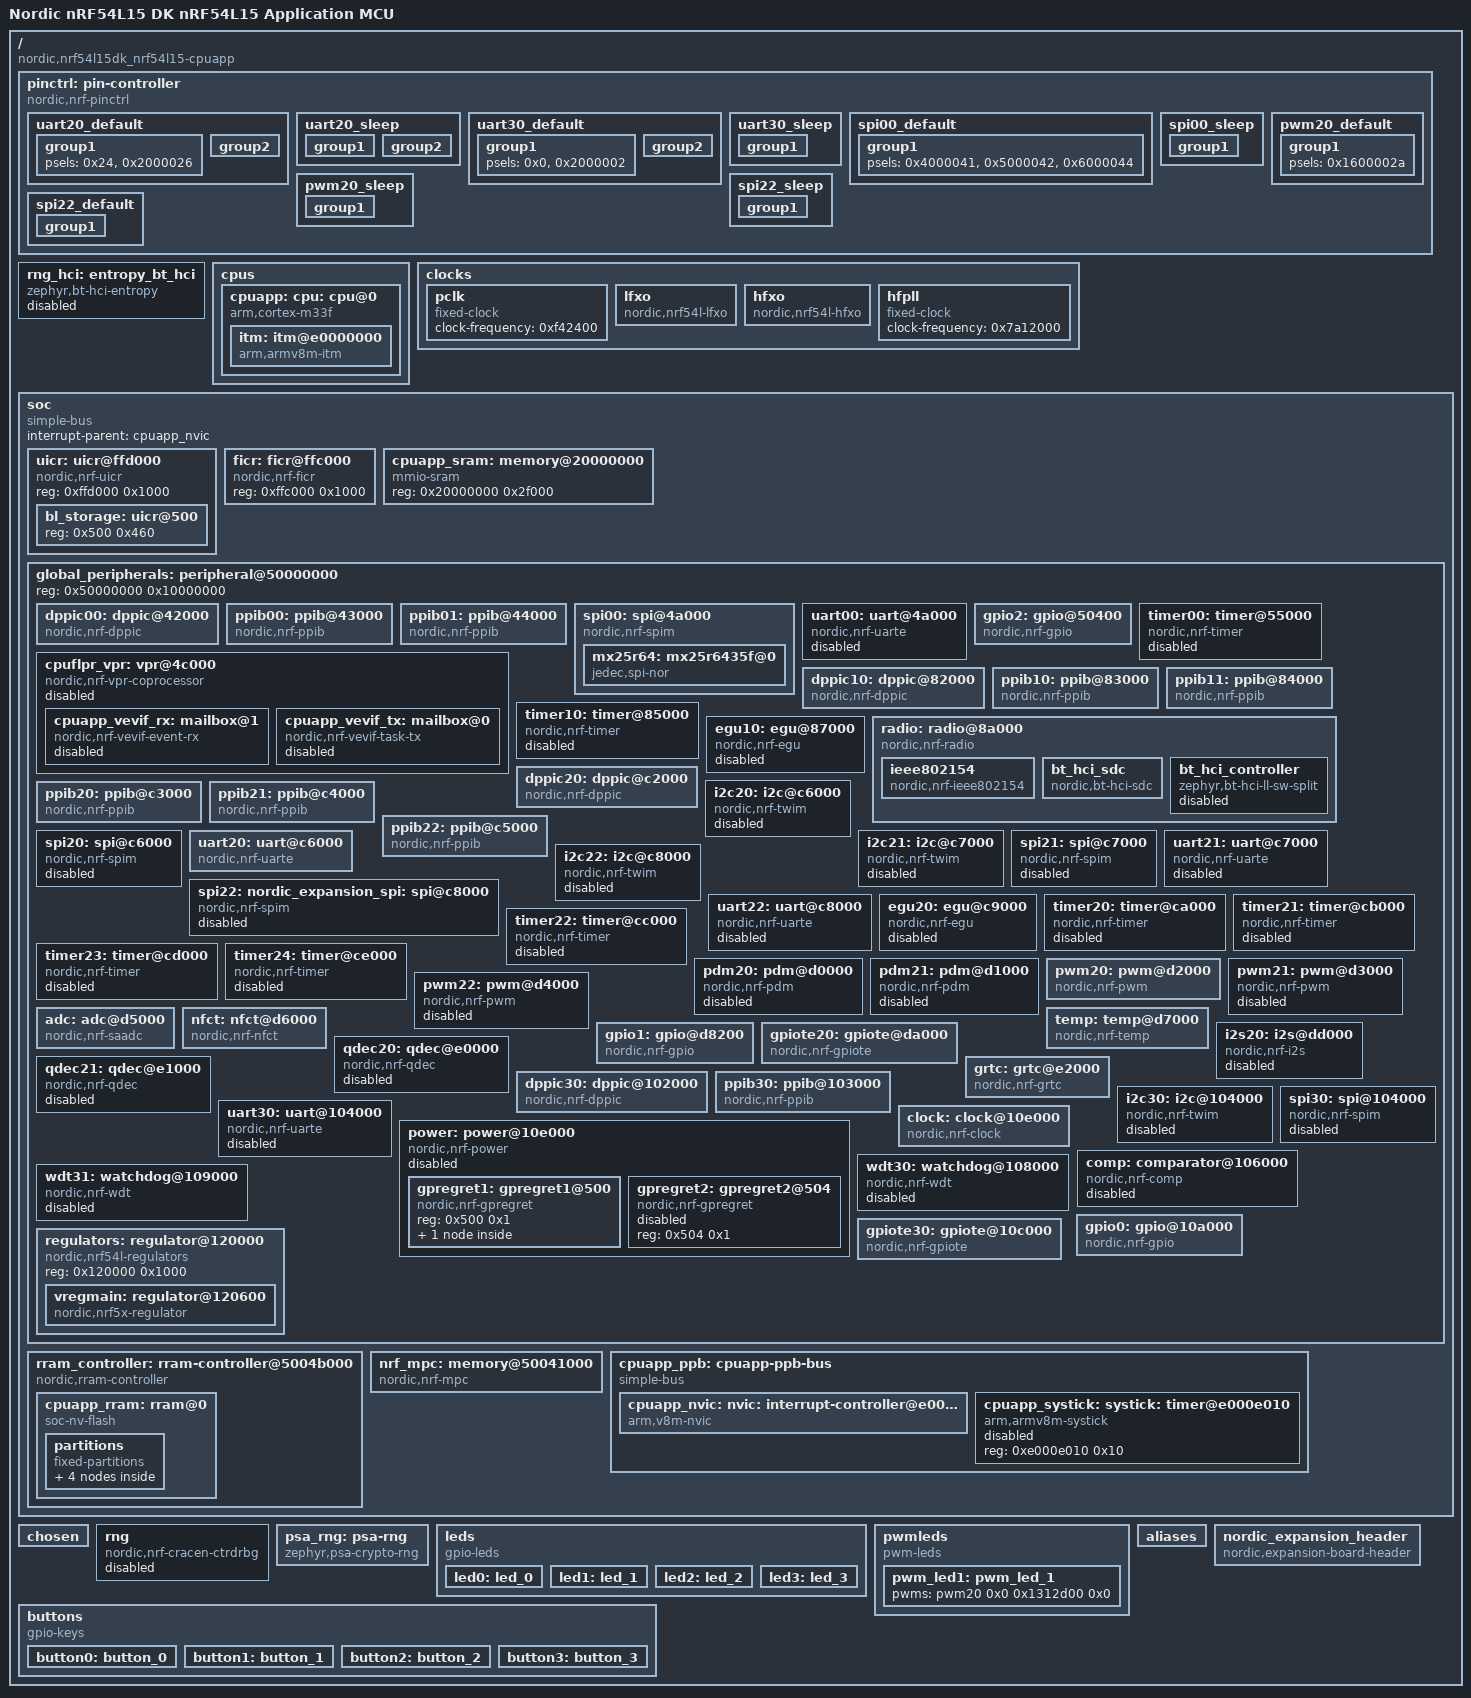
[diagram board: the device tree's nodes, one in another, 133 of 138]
/dts-v1/;

/* node '/' defined in zephyr/dts/vendor/nordic/nrf_common.dtsi:25 */
/ {
	#address-cells = < 0x1 >;                              /* in zephyr/dts/vendor/nordic/nrf54l_05_10_15.dtsi:19 */
	#size-cells = < 0x1 >;                                 /* in zephyr/dts/vendor/nordic/nrf54l_05_10_15.dtsi:20 */
	compatible = "nordic,nrf54l15dk_nrf54l15-cpuapp";      /* in zephyr/boards/nordic/nrf54l15dk/nrf54l15dk_nrf54l15_cpuapp.dts:13 */
	model = "Nordic nRF54L15 DK nRF54L15 Application MCU"; /* in zephyr/boards/nordic/nrf54l15dk/nrf54l15dk_nrf54l15_cpuapp.dts:14 */

	/* node '/pin-controller' defined in zephyr/dts/vendor/nordic/nrf_common.dtsi:26 */
	pinctrl: pin-controller {
		compatible = "nordic,nrf-pinctrl"; /* in zephyr/dts/vendor/nordic/nrf_common.dtsi:31 */

		/* node '/pin-controller/uart20_default' defined in zephyr/boards/nordic/nrf54l15dk/nrf54l15dk_nrf54l_05_10_15-pinctrl.dtsi:7 */
		uart20_default: uart20_default {
			phandle = < 0x7 >; /* in zephyr/boards/nordic/nrf54l15dk/nrf54l15dk_common.dtsi:114 */

			/* node '/pin-controller/uart20_default/group1' defined in zephyr/boards/nordic/nrf54l15dk/nrf54l15dk_nrf54l_05_10_15-pinctrl.dtsi:8 */
			group1 {
				psels = < 0x24 >,
				        < 0x2000026 >; /* in zephyr/boards/nordic/nrf54l15dk/nrf54l15dk_nrf54l_05_10_15-pinctrl.dtsi:9 */
			};

			/* node '/pin-controller/uart20_default/group2' defined in zephyr/boards/nordic/nrf54l15dk/nrf54l15dk_nrf54l_05_10_15-pinctrl.dtsi:13 */
			group2 {
				psels = < 0x1000025 >,
				        < 0x3000027 >; /* in zephyr/boards/nordic/nrf54l15dk/nrf54l15dk_nrf54l_05_10_15-pinctrl.dtsi:14 */
				bias-pull-up;          /* in zephyr/boards/nordic/nrf54l15dk/nrf54l15dk_nrf54l_05_10_15-pinctrl.dtsi:16 */
			};
		};

		/* node '/pin-controller/uart20_sleep' defined in zephyr/boards/nordic/nrf54l15dk/nrf54l15dk_nrf54l_05_10_15-pinctrl.dtsi:20 */
		uart20_sleep: uart20_sleep {
			phandle = < 0x8 >; /* in zephyr/boards/nordic/nrf54l15dk/nrf54l15dk_common.dtsi:115 */

			/* node '/pin-controller/uart20_sleep/group1' defined in zephyr/boards/nordic/nrf54l15dk/nrf54l15dk_nrf54l_05_10_15-pinctrl.dtsi:21 */
			group1 {
				psels = < 0x1000025 >,
				        < 0x2000026 >,
				        < 0x3000027 >; /* in zephyr/boards/nordic/nrf54l15dk/nrf54l15dk_nrf54l_05_10_15-pinctrl.dtsi:22 */
				low-power-enable;      /* in zephyr/boards/nordic/nrf54l15dk/nrf54l15dk_nrf54l_05_10_15-pinctrl.dtsi:25 */
			};

			/* node '/pin-controller/uart20_sleep/group2' defined in zephyr/boards/nordic/nrf54l15dk/nrf54l15dk_nrf54l_05_10_15-pinctrl.dtsi:28 */
			group2 {
				psels = < 0x24 >; /* in zephyr/boards/nordic/nrf54l15dk/nrf54l15dk_nrf54l_05_10_15-pinctrl.dtsi:29 */
				low-power-enable; /* in zephyr/boards/nordic/nrf54l15dk/nrf54l15dk_nrf54l_05_10_15-pinctrl.dtsi:30 */
				bias-pull-up;     /* in zephyr/boards/nordic/nrf54l15dk/nrf54l15dk_nrf54l_05_10_15-pinctrl.dtsi:31 */
			};
		};

		/* node '/pin-controller/uart30_default' defined in zephyr/boards/nordic/nrf54l15dk/nrf54l15dk_nrf54l_05_10_15-pinctrl.dtsi:35 */
		uart30_default: uart30_default {
			phandle = < 0x11 >; /* in zephyr/boards/nordic/nrf54l15dk/nrf54l15dk_common.dtsi:121 */

			/* node '/pin-controller/uart30_default/group1' defined in zephyr/boards/nordic/nrf54l15dk/nrf54l15dk_nrf54l_05_10_15-pinctrl.dtsi:36 */
			group1 {
				psels = < 0x0 >,
				        < 0x2000002 >; /* in zephyr/boards/nordic/nrf54l15dk/nrf54l15dk_nrf54l_05_10_15-pinctrl.dtsi:37 */
			};

			/* node '/pin-controller/uart30_default/group2' defined in zephyr/boards/nordic/nrf54l15dk/nrf54l15dk_nrf54l_05_10_15-pinctrl.dtsi:41 */
			group2 {
				psels = < 0x1000001 >,
				        < 0x3000003 >; /* in zephyr/boards/nordic/nrf54l15dk/nrf54l15dk_nrf54l_05_10_15-pinctrl.dtsi:42 */
				bias-pull-up;          /* in zephyr/boards/nordic/nrf54l15dk/nrf54l15dk_nrf54l_05_10_15-pinctrl.dtsi:44 */
			};
		};

		/* node '/pin-controller/uart30_sleep' defined in zephyr/boards/nordic/nrf54l15dk/nrf54l15dk_nrf54l_05_10_15-pinctrl.dtsi:48 */
		uart30_sleep: uart30_sleep {
			phandle = < 0x12 >; /* in zephyr/boards/nordic/nrf54l15dk/nrf54l15dk_common.dtsi:122 */

			/* node '/pin-controller/uart30_sleep/group1' defined in zephyr/boards/nordic/nrf54l15dk/nrf54l15dk_nrf54l_05_10_15-pinctrl.dtsi:49 */
			group1 {
				psels = < 0x0 >,
				        < 0x1000001 >,
				        < 0x2000002 >,
				        < 0x3000003 >; /* in zephyr/boards/nordic/nrf54l15dk/nrf54l15dk_nrf54l_05_10_15-pinctrl.dtsi:50 */
				low-power-enable;      /* in zephyr/boards/nordic/nrf54l15dk/nrf54l15dk_nrf54l_05_10_15-pinctrl.dtsi:54 */
			};
		};

		/* node '/pin-controller/spi00_default' defined in zephyr/boards/nordic/nrf54l15dk/nrf54l15dk_nrf54l_05_10_15-pinctrl.dtsi:58 */
		spi00_default: spi00_default {
			phandle = < 0x4 >; /* in zephyr/boards/nordic/nrf54l15dk/nrf54l_05_10_15_cpuapp_common.dtsi:117 */

			/* node '/pin-controller/spi00_default/group1' defined in zephyr/boards/nordic/nrf54l15dk/nrf54l15dk_nrf54l_05_10_15-pinctrl.dtsi:59 */
			group1 {
				psels = < 0x4000041 >,
				        < 0x5000042 >,
				        < 0x6000044 >; /* in zephyr/boards/nordic/nrf54l15dk/nrf54l15dk_nrf54l_05_10_15-pinctrl.dtsi:60 */
			};
		};

		/* node '/pin-controller/spi00_sleep' defined in zephyr/boards/nordic/nrf54l15dk/nrf54l15dk_nrf54l_05_10_15-pinctrl.dtsi:66 */
		spi00_sleep: spi00_sleep {
			phandle = < 0x5 >; /* in zephyr/boards/nordic/nrf54l15dk/nrf54l_05_10_15_cpuapp_common.dtsi:118 */

			/* node '/pin-controller/spi00_sleep/group1' defined in zephyr/boards/nordic/nrf54l15dk/nrf54l15dk_nrf54l_05_10_15-pinctrl.dtsi:67 */
			group1 {
				psels = < 0x4000041 >,
				        < 0x5000042 >,
				        < 0x6000044 >; /* in zephyr/boards/nordic/nrf54l15dk/nrf54l15dk_nrf54l_05_10_15-pinctrl.dtsi:68 */
				low-power-enable;      /* in zephyr/boards/nordic/nrf54l15dk/nrf54l15dk_nrf54l_05_10_15-pinctrl.dtsi:71 */
			};
		};

		/* node '/pin-controller/pwm20_default' defined in zephyr/boards/nordic/nrf54l15dk/nrf54l15dk_nrf54l_05_10_15-pinctrl.dtsi:75 */
		pwm20_default: pwm20_default {
			phandle = < 0xc >; /* in zephyr/boards/nordic/nrf54l15dk/nrf54l15dk_common.dtsi:128 */

			/* node '/pin-controller/pwm20_default/group1' defined in zephyr/boards/nordic/nrf54l15dk/nrf54l15dk_nrf54l_05_10_15-pinctrl.dtsi:76 */
			group1 {
				psels = < 0x1600002a >; /* in zephyr/boards/nordic/nrf54l15dk/nrf54l15dk_nrf54l_05_10_15-pinctrl.dtsi:77 */
			};
		};

		/* node '/pin-controller/pwm20_sleep' defined in zephyr/boards/nordic/nrf54l15dk/nrf54l15dk_nrf54l_05_10_15-pinctrl.dtsi:81 */
		pwm20_sleep: pwm20_sleep {
			phandle = < 0xd >; /* in zephyr/boards/nordic/nrf54l15dk/nrf54l15dk_common.dtsi:129 */

			/* node '/pin-controller/pwm20_sleep/group1' defined in zephyr/boards/nordic/nrf54l15dk/nrf54l15dk_nrf54l_05_10_15-pinctrl.dtsi:82 */
			group1 {
				psels = < 0x1600002a >; /* in zephyr/boards/nordic/nrf54l15dk/nrf54l15dk_nrf54l_05_10_15-pinctrl.dtsi:83 */
				low-power-enable;       /* in zephyr/boards/nordic/nrf54l15dk/nrf54l15dk_nrf54l_05_10_15-pinctrl.dtsi:84 */
			};
		};

		/* node '/pin-controller/spi22_default' defined in zephyr/boards/nordic/nrf54l15dk/nrf54l15dk_nrf54l_05_10_15-pinctrl.dtsi:103 */
		spi22_default: spi22_default {
			phandle = < 0xa >; /* in zephyr/boards/nordic/nrf54l15dk/nrf54l_05_10_15_cpuapp_common.dtsi:149 */

			/* node '/pin-controller/spi22_default/group1' defined in zephyr/boards/nordic/nrf54l15dk/nrf54l15dk_nrf54l_05_10_15-pinctrl.dtsi:104 */
			group1 {
				psels = < 0x400002b >,
				        < 0x6000027 >,
				        < 0x5000026 >; /* in zephyr/boards/nordic/nrf54l15dk/nrf54l15dk_nrf54l_05_10_15-pinctrl.dtsi:105 */
				bias-pull-down;        /* in zephyr/boards/nordic/nrf54l15dk/nrf54l15dk_nrf54l_05_10_15-pinctrl.dtsi:108 */
			};
		};

		/* node '/pin-controller/spi22_sleep' defined in zephyr/boards/nordic/nrf54l15dk/nrf54l15dk_nrf54l_05_10_15-pinctrl.dtsi:112 */
		spi22_sleep: spi22_sleep {
			phandle = < 0xb >; /* in zephyr/boards/nordic/nrf54l15dk/nrf54l_05_10_15_cpuapp_common.dtsi:150 */

			/* node '/pin-controller/spi22_sleep/group1' defined in zephyr/boards/nordic/nrf54l15dk/nrf54l15dk_nrf54l_05_10_15-pinctrl.dtsi:113 */
			group1 {
				psels = < 0x400002b >,
				        < 0x6000027 >,
				        < 0x5000026 >; /* in zephyr/boards/nordic/nrf54l15dk/nrf54l15dk_nrf54l_05_10_15-pinctrl.dtsi:114 */
				bias-pull-down;        /* in zephyr/boards/nordic/nrf54l15dk/nrf54l15dk_nrf54l_05_10_15-pinctrl.dtsi:117 */
				low-power-enable;      /* in zephyr/boards/nordic/nrf54l15dk/nrf54l15dk_nrf54l_05_10_15-pinctrl.dtsi:118 */
			};
		};
	};

	/* node '/entropy_bt_hci' defined in zephyr/dts/vendor/nordic/nrf_common.dtsi:34 */
	rng_hci: entropy_bt_hci {
		compatible = "zephyr,bt-hci-entropy"; /* in zephyr/dts/vendor/nordic/nrf_common.dtsi:35 */
		status = "disabled";                  /* in zephyr/dts/vendor/nordic/nrf_common.dtsi:36 */
	};

	/* node '/cpus' defined in zephyr/dts/vendor/nordic/nrf54l_05_10_15.dtsi:22 */
	cpus {
		#address-cells = < 0x1 >; /* in zephyr/dts/vendor/nordic/nrf54l_05_10_15.dtsi:23 */
		#size-cells = < 0x0 >;    /* in zephyr/dts/vendor/nordic/nrf54l_05_10_15.dtsi:24 */

		/* node '/cpus/cpu@0' defined in zephyr/dts/vendor/nordic/nrf54l_05_10_15.dtsi:26 */
		cpuapp: cpu: cpu@0 {
			compatible = "arm,cortex-m33f"; /* in zephyr/dts/vendor/nordic/nrf54l_05_10_15.dtsi:27 */
			reg = < 0x0 >;                  /* in zephyr/dts/vendor/nordic/nrf54l_05_10_15.dtsi:28 */
			device_type = "cpu";            /* in zephyr/dts/vendor/nordic/nrf54l_05_10_15.dtsi:29 */
			clocks = < &hfpll >;            /* in zephyr/dts/vendor/nordic/nrf54l_05_10_15.dtsi:30 */
			#address-cells = < 0x1 >;       /* in zephyr/dts/vendor/nordic/nrf54l_05_10_15.dtsi:31 */
			#size-cells = < 0x1 >;          /* in zephyr/dts/vendor/nordic/nrf54l_05_10_15.dtsi:32 */

			/* node '/cpus/cpu@0/itm@e0000000' defined in zephyr/dts/vendor/nordic/nrf54l_05_10_15.dtsi:34 */
			itm: itm@e0000000 {
				compatible = "arm,armv8m-itm";     /* in zephyr/dts/vendor/nordic/nrf54l_05_10_15.dtsi:35 */
				reg = < 0xe0000000 0x1000 >;       /* in zephyr/dts/vendor/nordic/nrf54l_05_10_15.dtsi:36 */
				swo-ref-frequency = < 0x7a12000 >; /* in zephyr/dts/vendor/nordic/nrf54l_05_10_15.dtsi:37 */
			};
		};
	};

	/* node '/clocks' defined in zephyr/dts/vendor/nordic/nrf54l_05_10_15.dtsi:52 */
	clocks {

		/* node '/clocks/pclk' defined in zephyr/dts/vendor/nordic/nrf54l_05_10_15.dtsi:53 */
		pclk: pclk {
			compatible = "fixed-clock";     /* in zephyr/dts/vendor/nordic/nrf54l_05_10_15.dtsi:54 */
			#clock-cells = < 0x0 >;         /* in zephyr/dts/vendor/nordic/nrf54l_05_10_15.dtsi:55 */
			clock-frequency = < 0xf42400 >; /* in zephyr/dts/vendor/nordic/nrf54l_05_10_15.dtsi:56 */
			phandle = < 0x10 >;             /* in zephyr/dts/vendor/nordic/nrf54l_05_10_15.dtsi:595 */
		};

		/* node '/clocks/lfxo' defined in zephyr/dts/vendor/nordic/nrf54l_05_10_15.dtsi:59 */
		lfxo: lfxo {
			compatible = "nordic,nrf54l-lfxo";        /* in zephyr/dts/vendor/nordic/nrf54l_05_10_15.dtsi:60 */
			#clock-cells = < 0x0 >;                   /* in zephyr/dts/vendor/nordic/nrf54l_05_10_15.dtsi:61 */
			clock-frequency = < 0x8000 >;             /* in zephyr/dts/vendor/nordic/nrf54l_05_10_15.dtsi:62 */
			load-capacitors = "internal";             /* in zephyr/boards/nordic/nrf54l15dk/nrf54l_05_10_15_cpuapp_common.dtsi:35 */
			load-capacitance-femtofarad = < 0x4268 >; /* in zephyr/boards/nordic/nrf54l15dk/nrf54l_05_10_15_cpuapp_common.dtsi:36 */
			phandle = < 0xf >;                        /* in zephyr/dts/vendor/nordic/nrf54l_05_10_15.dtsi:595 */
		};

		/* node '/clocks/hfxo' defined in zephyr/dts/vendor/nordic/nrf54l_05_10_15.dtsi:65 */
		hfxo: hfxo {
			compatible = "nordic,nrf54l-hfxo";        /* in zephyr/dts/vendor/nordic/nrf54l_05_10_15.dtsi:66 */
			#clock-cells = < 0x0 >;                   /* in zephyr/dts/vendor/nordic/nrf54l_05_10_15.dtsi:67 */
			clock-frequency = < 0x1e84800 >;          /* in zephyr/dts/vendor/nordic/nrf54l_05_10_15.dtsi:68 */
			startup-time-us = < 0x672 >;              /* in zephyr/dts/vendor/nordic/nrf54l_05_10_15.dtsi:69 */
			load-capacitors = "internal";             /* in zephyr/boards/nordic/nrf54l15dk/nrf54l_05_10_15_cpuapp_common.dtsi:40 */
			load-capacitance-femtofarad = < 0x3a98 >; /* in zephyr/boards/nordic/nrf54l15dk/nrf54l_05_10_15_cpuapp_common.dtsi:41 */
			phandle = < 0x6 >;                        /* in zephyr/dts/vendor/nordic/nrf54l_05_10_15.dtsi:242 */
		};

		/* node '/clocks/hfpll' defined in zephyr/dts/vendor/nordic/nrf54l_05_10_15.dtsi:72 */
		hfpll: hfpll {
			compatible = "fixed-clock";      /* in zephyr/dts/vendor/nordic/nrf54l_05_10_15.dtsi:73 */
			#clock-cells = < 0x0 >;          /* in zephyr/dts/vendor/nordic/nrf54l_05_10_15.dtsi:74 */
			clock-frequency = < 0x7a12000 >; /* in zephyr/dts/vendor/nordic/nrf54l_05_10_15.dtsi:75 */
			phandle = < 0x1 >;               /* in zephyr/dts/vendor/nordic/nrf54l_05_10_15.dtsi:30 */
		};
	};

	/* node '/soc' defined in zephyr/dts/vendor/nordic/nrf54l_05_10_15.dtsi:79 */
	soc {
		#address-cells = < 0x1 >;            /* in zephyr/dts/vendor/nordic/nrf54l_05_10_15.dtsi:80 */
		#size-cells = < 0x1 >;               /* in zephyr/dts/vendor/nordic/nrf54l_05_10_15.dtsi:81 */
		compatible = "simple-bus";           /* in zephyr/dts/arm/nordic/nrf54l_05_10_15_cpuapp.dtsi:28 */
		interrupt-parent = < &cpuapp_nvic >; /* in zephyr/dts/arm/nordic/nrf54l_05_10_15_cpuapp.dtsi:29 */
		ranges;                              /* in zephyr/dts/arm/nordic/nrf54l_05_10_15_cpuapp.dtsi:30 */

		/* node '/soc/uicr@ffd000' defined in zephyr/dts/vendor/nordic/nrf54l_05_10_15.dtsi:86 */
		uicr: uicr@ffd000 {
			compatible = "nordic,nrf-uicr";   /* in zephyr/dts/vendor/nordic/nrf54l_05_10_15.dtsi:87 */
			reg = < 0xffd000 0x1000 >;        /* in zephyr/dts/vendor/nordic/nrf54l_05_10_15.dtsi:88 */
			ranges = < 0x0 0xffd000 0x1000 >; /* in zephyr/dts/vendor/nordic/nrf54l_05_10_15.dtsi:89 */
			#address-cells = < 0x1 >;         /* in zephyr/dts/vendor/nordic/nrf54l_05_10_15.dtsi:90 */
			#size-cells = < 0x1 >;            /* in zephyr/dts/vendor/nordic/nrf54l_05_10_15.dtsi:91 */

			/* node '/soc/uicr@ffd000/uicr@500' defined in zephyr/dts/vendor/nordic/nrf54l15_cpuapp_partition.dtsi:36 */
			bl_storage: uicr@500 {
				reg = < 0x500 0x460 >; /* in zephyr/dts/vendor/nordic/nrf54l15_cpuapp_partition.dtsi:37 */
			};
		};

		/* node '/soc/ficr@ffc000' defined in zephyr/dts/vendor/nordic/nrf54l_05_10_15.dtsi:95 */
		ficr: ficr@ffc000 {
			compatible = "nordic,nrf-ficr"; /* in zephyr/dts/vendor/nordic/nrf54l_05_10_15.dtsi:96 */
			reg = < 0xffc000 0x1000 >;      /* in zephyr/dts/vendor/nordic/nrf54l_05_10_15.dtsi:97 */
			#nordic,ficr-cells = < 0x1 >;   /* in zephyr/dts/vendor/nordic/nrf54l_05_10_15.dtsi:98 */
		};

		/* node '/soc/memory@20000000' defined in zephyr/dts/vendor/nordic/nrf54l_05_10_15.dtsi:101 */
		cpuapp_sram: memory@20000000 {
			compatible = "mmio-sram";            /* in zephyr/dts/vendor/nordic/nrf54l_05_10_15.dtsi:102 */
			#address-cells = < 0x1 >;            /* in zephyr/dts/vendor/nordic/nrf54l_05_10_15.dtsi:103 */
			#size-cells = < 0x1 >;               /* in zephyr/dts/vendor/nordic/nrf54l_05_10_15.dtsi:104 */
			reg = < 0x20000000 0x2f000 >;        /* in zephyr/dts/vendor/nordic/nrf54l15.dtsi:10 */
			ranges = < 0x0 0x20000000 0x2f000 >; /* in zephyr/dts/vendor/nordic/nrf54l15.dtsi:11 */
			status = "okay";                     /* in zephyr/boards/nordic/nrf54l15dk/nrf54l_05_10_15_cpuapp_common.dtsi:31 */
		};

		/* node '/soc/peripheral@50000000' defined in zephyr/dts/vendor/nordic/nrf54l_05_10_15.dtsi:114 */
		global_peripherals: peripheral@50000000 {
			reg = < 0x50000000 0x10000000 >;        /* in zephyr/dts/vendor/nordic/nrf54l_05_10_15.dtsi:115 */
			#address-cells = < 0x1 >;               /* in zephyr/dts/vendor/nordic/nrf54l_05_10_15.dtsi:116 */
			#size-cells = < 0x1 >;                  /* in zephyr/dts/vendor/nordic/nrf54l_05_10_15.dtsi:117 */
			ranges = < 0x0 0x50000000 0x10000000 >; /* in zephyr/dts/vendor/nordic/nrf54l_05_10_15.dtsi:118 */

			/* node '/soc/peripheral@50000000/dppic@42000' defined in zephyr/dts/vendor/nordic/nrf54l_05_10_15.dtsi:121 */
			dppic00: dppic@42000 {
				compatible = "nordic,nrf-dppic"; /* in zephyr/dts/vendor/nordic/nrf54l_05_10_15.dtsi:122 */
				reg = < 0x42000 0x808 >;         /* in zephyr/dts/vendor/nordic/nrf54l_05_10_15.dtsi:123 */
				channels = < 0x8 >;              /* in zephyr/dts/vendor/nordic/nrf54l_05_10_15.dtsi:125 */
				groups = < 0x2 >;                /* in zephyr/dts/vendor/nordic/nrf54l_05_10_15.dtsi:126 */
				status = "okay";                 /* in zephyr/dts/arm/nordic/nrf54l_05_10_15_cpuapp.dtsi:100 */
			};

			/* node '/soc/peripheral@50000000/ppib@43000' defined in zephyr/dts/vendor/nordic/nrf54l_05_10_15.dtsi:129 */
			ppib00: ppib@43000 {
				compatible = "nordic,nrf-ppib"; /* in zephyr/dts/vendor/nordic/nrf54l_05_10_15.dtsi:130 */
				reg = < 0x43000 0x1000 >;       /* in zephyr/dts/vendor/nordic/nrf54l_05_10_15.dtsi:131 */
				channels = < 0x8 >;             /* in zephyr/dts/vendor/nordic/nrf54l_05_10_15.dtsi:133 */
				status = "okay";                /* in zephyr/dts/arm/nordic/nrf54l_05_10_15_cpuapp.dtsi:116 */
			};

			/* node '/soc/peripheral@50000000/ppib@44000' defined in zephyr/dts/vendor/nordic/nrf54l_05_10_15.dtsi:136 */
			ppib01: ppib@44000 {
				compatible = "nordic,nrf-ppib"; /* in zephyr/dts/vendor/nordic/nrf54l_05_10_15.dtsi:137 */
				reg = < 0x44000 0x1000 >;       /* in zephyr/dts/vendor/nordic/nrf54l_05_10_15.dtsi:138 */
				channels = < 0x8 >;             /* in zephyr/dts/vendor/nordic/nrf54l_05_10_15.dtsi:140 */
				status = "okay";                /* in zephyr/dts/arm/nordic/nrf54l_05_10_15_cpuapp.dtsi:120 */
			};

			/* node '/soc/peripheral@50000000/spi@4a000' defined in zephyr/dts/vendor/nordic/nrf54l_05_10_15.dtsi:143 */
			spi00: spi@4a000 {
				compatible = "nordic,nrf-spim"; /* in zephyr/dts/vendor/nordic/nrf54l_05_10_15.dtsi:150 */
				#address-cells = < 0x1 >;       /* in zephyr/dts/vendor/nordic/nrf54l_05_10_15.dtsi:151 */
				#size-cells = < 0x0 >;          /* in zephyr/dts/vendor/nordic/nrf54l_05_10_15.dtsi:152 */
				reg = < 0x4a000 0x1000 >;       /* in zephyr/dts/vendor/nordic/nrf54l_05_10_15.dtsi:153 */
				interrupts = < 0x4a 0x1 >;      /* in zephyr/dts/vendor/nordic/nrf54l_05_10_15.dtsi:154 */
				clocks = < &hfpll >;            /* in zephyr/dts/vendor/nordic/nrf54l_05_10_15.dtsi:155 */
				max-frequency = < 0x1e84800 >;  /* in zephyr/dts/vendor/nordic/nrf54l_05_10_15.dtsi:156 */
				easydma-maxcnt-bits = < 0x10 >; /* in zephyr/dts/vendor/nordic/nrf54l_05_10_15.dtsi:157 */
				rx-delay-supported;             /* in zephyr/dts/vendor/nordic/nrf54l_05_10_15.dtsi:158 */
				rx-delay = < 0x1 >;             /* in zephyr/dts/vendor/nordic/nrf54l_05_10_15.dtsi:159 */
				status = "okay";                /* in zephyr/boards/nordic/nrf54l15dk/nrf54l_05_10_15_cpuapp_common.dtsi:115 */
				cs-gpios = < &gpio2 0x5 0x1 >;  /* in zephyr/boards/nordic/nrf54l15dk/nrf54l_05_10_15_cpuapp_common.dtsi:116 */
				pinctrl-0 = < &spi00_default >; /* in zephyr/boards/nordic/nrf54l15dk/nrf54l_05_10_15_cpuapp_common.dtsi:117 */
				pinctrl-1 = < &spi00_sleep >;   /* in zephyr/boards/nordic/nrf54l15dk/nrf54l_05_10_15_cpuapp_common.dtsi:118 */
				pinctrl-names = "default",
				                "sleep";        /* in zephyr/boards/nordic/nrf54l15dk/nrf54l_05_10_15_cpuapp_common.dtsi:119 */

				/* node '/soc/peripheral@50000000/spi@4a000/mx25r6435f@0' defined in zephyr/boards/nordic/nrf54l15dk/nrf54l_05_10_15_cpuapp_common.dtsi:121 */
				mx25r64: mx25r6435f@0 {
					compatible = "jedec,spi-nor";                                                                 /* in zephyr/boards/nordic/nrf54l15dk/nrf54l_05_10_15_cpuapp_common.dtsi:122 */
					status = "okay";                                                                              /* in zephyr/boards/nordic/nrf54l15dk/nrf54l_05_10_15_cpuapp_common.dtsi:123 */
					reg = < 0x0 >;                                                                                /* in zephyr/boards/nordic/nrf54l15dk/nrf54l_05_10_15_cpuapp_common.dtsi:124 */
					spi-max-frequency = < 0x7a1200 >;                                                             /* in zephyr/boards/nordic/nrf54l15dk/nrf54l_05_10_15_cpuapp_common.dtsi:125 */
					jedec-id = [ C2 28 17 ];                                                                      /* in zephyr/boards/nordic/nrf54l15dk/nrf54l_05_10_15_cpuapp_common.dtsi:126 */
					sfdp-bfp = [ E5 20 F1 FF FF FF FF 03 44 EB 08 6B 08 3B 04 BB EE FF FF FF FF FF 00 FF FF FF 00
					             FF 0C 20 0F 52 10 D8 00 FF 23 72 F5 00 82 ED 04 CC 44 83 48 44 30 B0 30 B0 F7 C4
					             D5 5C 00 BE 29 FF F0 D0 FF FF ];                                                 /* in zephyr/boards/nordic/nrf54l15dk/nrf54l_05_10_15_cpuapp_common.dtsi:127 */
					size = < 0x4000000 >;                                                                         /* in zephyr/boards/nordic/nrf54l15dk/nrf54l_05_10_15_cpuapp_common.dtsi:131 */
					has-dpd;                                                                                      /* in zephyr/boards/nordic/nrf54l15dk/nrf54l_05_10_15_cpuapp_common.dtsi:132 */
					t-enter-dpd = < 0x2710 >;                                                                     /* in zephyr/boards/nordic/nrf54l15dk/nrf54l_05_10_15_cpuapp_common.dtsi:133 */
					t-exit-dpd = < 0x88b8 >;                                                                      /* in zephyr/boards/nordic/nrf54l15dk/nrf54l_05_10_15_cpuapp_common.dtsi:134 */
					reset-gpios = < &gpio2 0x0 0x1 >;                                                             /* in zephyr/boards/nordic/nrf54l15dk/nrf54l_05_10_15_cpuapp_common.dtsi:135 */
				};
			};

			/* node '/soc/peripheral@50000000/uart@4a000' defined in zephyr/dts/vendor/nordic/nrf54l_05_10_15.dtsi:163 */
			uart00: uart@4a000 {
				compatible = "nordic,nrf-uarte"; /* in zephyr/dts/vendor/nordic/nrf54l_05_10_15.dtsi:164 */
				reg = < 0x4a000 0x1000 >;        /* in zephyr/dts/vendor/nordic/nrf54l_05_10_15.dtsi:165 */
				interrupts = < 0x4a 0x1 >;       /* in zephyr/dts/vendor/nordic/nrf54l_05_10_15.dtsi:166 */
				clocks = < &hfpll >;             /* in zephyr/dts/vendor/nordic/nrf54l_05_10_15.dtsi:167 */
				status = "disabled";             /* in zephyr/dts/vendor/nordic/nrf54l_05_10_15.dtsi:168 */
				endtx-stoptx-supported;          /* in zephyr/dts/vendor/nordic/nrf54l_05_10_15.dtsi:169 */
				frame-timeout-supported;         /* in zephyr/dts/vendor/nordic/nrf54l_05_10_15.dtsi:170 */
			};

			/* node '/soc/peripheral@50000000/vpr@4c000' defined in zephyr/dts/vendor/nordic/nrf54l_05_10_15.dtsi:173 */
			cpuflpr_vpr: vpr@4c000 {
				compatible = "nordic,nrf-vpr-coprocessor"; /* in zephyr/dts/vendor/nordic/nrf54l_05_10_15.dtsi:174 */
				reg = < 0x4c000 0x1000 >;                  /* in zephyr/dts/vendor/nordic/nrf54l_05_10_15.dtsi:175 */
				ranges = < 0x0 0x4c000 0x1000 >;           /* in zephyr/dts/vendor/nordic/nrf54l_05_10_15.dtsi:176 */
				#address-cells = < 0x1 >;                  /* in zephyr/dts/vendor/nordic/nrf54l_05_10_15.dtsi:177 */
				#size-cells = < 0x1 >;                     /* in zephyr/dts/vendor/nordic/nrf54l_05_10_15.dtsi:178 */
				status = "disabled";                       /* in zephyr/dts/vendor/nordic/nrf54l_05_10_15.dtsi:179 */
				enable-secure;                             /* in zephyr/dts/vendor/nordic/nrf54l_05_10_15.dtsi:180 */

				/* node '/soc/peripheral@50000000/vpr@4c000/mailbox@1' defined in zephyr/dts/arm/nordic/nrf54l_05_10_15_cpuapp.dtsi:49 */
				cpuapp_vevif_rx: mailbox@1 {
					compatible = "nordic,nrf-vevif-event-rx"; /* in zephyr/dts/arm/nordic/nrf54l_05_10_15_cpuapp.dtsi:50 */
					reg = < 0x1 0x1000 >;                     /* in zephyr/dts/arm/nordic/nrf54l_05_10_15_cpuapp.dtsi:51 */
					status = "disabled";                      /* in zephyr/dts/arm/nordic/nrf54l_05_10_15_cpuapp.dtsi:52 */
					interrupts = < 0x4c 0x1 >;                /* in zephyr/dts/arm/nordic/nrf54l_05_10_15_cpuapp.dtsi:53 */
					#mbox-cells = < 0x1 >;                    /* in zephyr/dts/arm/nordic/nrf54l_05_10_15_cpuapp.dtsi:54 */
					nordic,events = < 0x1 >;                  /* in zephyr/dts/arm/nordic/nrf54l_05_10_15_cpuapp.dtsi:55 */
					nordic,events-mask = < 0x100000 >;        /* in zephyr/dts/arm/nordic/nrf54l_05_10_15_cpuapp.dtsi:56 */
				};

				/* node '/soc/peripheral@50000000/vpr@4c000/mailbox@0' defined in zephyr/dts/arm/nordic/nrf54l_05_10_15_cpuapp.dtsi:59 */
				cpuapp_vevif_tx: mailbox@0 {
					compatible = "nordic,nrf-vevif-task-tx"; /* in zephyr/dts/arm/nordic/nrf54l_05_10_15_cpuapp.dtsi:60 */
					reg = < 0x0 0x1000 >;                    /* in zephyr/dts/arm/nordic/nrf54l_05_10_15_cpuapp.dtsi:61 */
					#mbox-cells = < 0x1 >;                   /* in zephyr/dts/arm/nordic/nrf54l_05_10_15_cpuapp.dtsi:62 */
					nordic,tasks = < 0x7 >;                  /* in zephyr/dts/arm/nordic/nrf54l_05_10_15_cpuapp.dtsi:63 */
					nordic,tasks-mask = < 0x7f0000 >;        /* in zephyr/dts/arm/nordic/nrf54l_05_10_15_cpuapp.dtsi:64 */
					status = "disabled";                     /* in zephyr/dts/arm/nordic/nrf54l_05_10_15_cpuapp.dtsi:65 */
				};
			};

			/* node '/soc/peripheral@50000000/gpio@50400' defined in zephyr/dts/vendor/nordic/nrf54l_05_10_15.dtsi:192 */
			gpio2: gpio@50400 {
				compatible = "nordic,nrf-gpio"; /* in zephyr/dts/vendor/nordic/nrf54l_05_10_15.dtsi:193 */
				gpio-controller;                /* in zephyr/dts/vendor/nordic/nrf54l_05_10_15.dtsi:194 */
				reg = < 0x50400 0x300 >;        /* in zephyr/dts/vendor/nordic/nrf54l_05_10_15.dtsi:195 */
				#gpio-cells = < 0x2 >;          /* in zephyr/dts/vendor/nordic/nrf54l_05_10_15.dtsi:196 */
				ngpios = < 0xb >;               /* in zephyr/dts/vendor/nordic/nrf54l_05_10_15.dtsi:197 */
				port = < 0x2 >;                 /* in zephyr/dts/vendor/nordic/nrf54l_05_10_15.dtsi:199 */
				status = "okay";                /* in zephyr/boards/nordic/nrf54l15dk/nrf54l_05_10_15_cpuapp_common.dtsi:77 */
				phandle = < 0x3 >;              /* in zephyr/boards/nordic/nrf54l15dk/nrf54l_05_10_15_cpuapp_common.dtsi:116 */
			};

			/* node '/soc/peripheral@50000000/timer@55000' defined in zephyr/dts/vendor/nordic/nrf54l_05_10_15.dtsi:202 */
			timer00: timer@55000 {
				compatible = "nordic,nrf-timer"; /* in zephyr/dts/vendor/nordic/nrf54l_05_10_15.dtsi:203 */
				status = "disabled";             /* in zephyr/dts/vendor/nordic/nrf54l_05_10_15.dtsi:204 */
				reg = < 0x55000 0x1000 >;        /* in zephyr/dts/vendor/nordic/nrf54l_05_10_15.dtsi:205 */
				cc-num = < 0x6 >;                /* in zephyr/dts/vendor/nordic/nrf54l_05_10_15.dtsi:206 */
				max-bit-width = < 0x20 >;        /* in zephyr/dts/vendor/nordic/nrf54l_05_10_15.dtsi:207 */
				interrupts = < 0x55 0x1 >;       /* in zephyr/dts/vendor/nordic/nrf54l_05_10_15.dtsi:208 */
				clocks = < &hfpll >;             /* in zephyr/dts/vendor/nordic/nrf54l_05_10_15.dtsi:209 */
				prescaler = < 0x0 >;             /* in zephyr/dts/vendor/nordic/nrf54l_05_10_15.dtsi:210 */
			};

			/* node '/soc/peripheral@50000000/dppic@82000' defined in zephyr/dts/vendor/nordic/nrf54l_05_10_15.dtsi:213 */
			dppic10: dppic@82000 {
				compatible = "nordic,nrf-dppic"; /* in zephyr/dts/vendor/nordic/nrf54l_05_10_15.dtsi:214 */
				reg = < 0x82000 0x808 >;         /* in zephyr/dts/vendor/nordic/nrf54l_05_10_15.dtsi:215 */
				channels = < 0x18 >;             /* in zephyr/dts/vendor/nordic/nrf54l_05_10_15.dtsi:217 */
				groups = < 0x6 >;                /* in zephyr/dts/vendor/nordic/nrf54l_05_10_15.dtsi:218 */
				status = "okay";                 /* in zephyr/dts/arm/nordic/nrf54l_05_10_15_cpuapp.dtsi:104 */
			};

			/* node '/soc/peripheral@50000000/ppib@83000' defined in zephyr/dts/vendor/nordic/nrf54l_05_10_15.dtsi:221 */
			ppib10: ppib@83000 {
				compatible = "nordic,nrf-ppib"; /* in zephyr/dts/vendor/nordic/nrf54l_05_10_15.dtsi:222 */
				reg = < 0x83000 0x1000 >;       /* in zephyr/dts/vendor/nordic/nrf54l_05_10_15.dtsi:223 */
				channels = < 0x8 >;             /* in zephyr/dts/vendor/nordic/nrf54l_05_10_15.dtsi:225 */
				status = "okay";                /* in zephyr/dts/arm/nordic/nrf54l_05_10_15_cpuapp.dtsi:124 */
			};

			/* node '/soc/peripheral@50000000/ppib@84000' defined in zephyr/dts/vendor/nordic/nrf54l_05_10_15.dtsi:228 */
			ppib11: ppib@84000 {
				compatible = "nordic,nrf-ppib"; /* in zephyr/dts/vendor/nordic/nrf54l_05_10_15.dtsi:229 */
				reg = < 0x84000 0x1000 >;       /* in zephyr/dts/vendor/nordic/nrf54l_05_10_15.dtsi:230 */
				channels = < 0x10 >;            /* in zephyr/dts/vendor/nordic/nrf54l_05_10_15.dtsi:232 */
				status = "okay";                /* in zephyr/dts/arm/nordic/nrf54l_05_10_15_cpuapp.dtsi:128 */
			};

			/* node '/soc/peripheral@50000000/timer@85000' defined in zephyr/dts/vendor/nordic/nrf54l_05_10_15.dtsi:235 */
			timer10: timer@85000 {
				compatible = "nordic,nrf-timer"; /* in zephyr/dts/vendor/nordic/nrf54l_05_10_15.dtsi:236 */
				status = "disabled";             /* in zephyr/dts/vendor/nordic/nrf54l_05_10_15.dtsi:237 */
				reg = < 0x85000 0x1000 >;        /* in zephyr/dts/vendor/nordic/nrf54l_05_10_15.dtsi:238 */
				cc-num = < 0x8 >;                /* in zephyr/dts/vendor/nordic/nrf54l_05_10_15.dtsi:239 */
				max-bit-width = < 0x20 >;        /* in zephyr/dts/vendor/nordic/nrf54l_05_10_15.dtsi:240 */
				interrupts = < 0x85 0x1 >;       /* in zephyr/dts/vendor/nordic/nrf54l_05_10_15.dtsi:241 */
				clocks = < &hfxo >;              /* in zephyr/dts/vendor/nordic/nrf54l_05_10_15.dtsi:242 */
				prescaler = < 0x0 >;             /* in zephyr/dts/vendor/nordic/nrf54l_05_10_15.dtsi:243 */
			};

			/* node '/soc/peripheral@50000000/egu@87000' defined in zephyr/dts/vendor/nordic/nrf54l_05_10_15.dtsi:246 */
			egu10: egu@87000 {
				compatible = "nordic,nrf-egu"; /* in zephyr/dts/vendor/nordic/nrf54l_05_10_15.dtsi:247 */
				reg = < 0x87000 0x1000 >;      /* in zephyr/dts/vendor/nordic/nrf54l_05_10_15.dtsi:248 */
				interrupts = < 0x87 0x1 >;     /* in zephyr/dts/vendor/nordic/nrf54l_05_10_15.dtsi:249 */
				status = "disabled";           /* in zephyr/dts/vendor/nordic/nrf54l_05_10_15.dtsi:250 */
			};

			/* node '/soc/peripheral@50000000/radio@8a000' defined in zephyr/dts/vendor/nordic/nrf54l_05_10_15.dtsi:253 */
			radio: radio@8a000 {
				compatible = "nordic,nrf-radio"; /* in zephyr/dts/vendor/nordic/nrf54l_05_10_15.dtsi:254 */
				reg = < 0x8a000 0x1000 >;        /* in zephyr/dts/vendor/nordic/nrf54l_05_10_15.dtsi:255 */
				interrupts = < 0x8a 0x1 >;       /* in zephyr/dts/vendor/nordic/nrf54l_05_10_15.dtsi:256 */
				dfe-supported;                   /* in zephyr/dts/vendor/nordic/nrf54l_05_10_15.dtsi:258 */
				ieee802154-supported;            /* in zephyr/dts/vendor/nordic/nrf54l_05_10_15.dtsi:259 */
				ble-2mbps-supported;             /* in zephyr/dts/vendor/nordic/nrf54l_05_10_15.dtsi:260 */
				ble-coded-phy-supported;         /* in zephyr/dts/vendor/nordic/nrf54l_05_10_15.dtsi:261 */
				ble-cs-supported;                /* in zephyr/dts/vendor/nordic/nrf54l_05_10_15.dtsi:262 */
				status = "okay";                 /* in zephyr/boards/nordic/nrf54l15dk/nrf54l_05_10_15_cpuapp_common.dtsi:89 */

				/* node '/soc/peripheral@50000000/radio@8a000/ieee802154' defined in zephyr/dts/vendor/nordic/nrf54l_05_10_15.dtsi:264 */
				ieee802154: ieee802154 {
					compatible = "nordic,nrf-ieee802154"; /* in zephyr/dts/vendor/nordic/nrf54l_05_10_15.dtsi:265 */
					status = "okay";                      /* in zephyr/boards/nordic/nrf54l15dk/nrf54l_05_10_15_cpuapp_common.dtsi:93 */
				};

				/* node '/soc/peripheral@50000000/radio@8a000/bt_hci_sdc' defined in zephyr/dts/vendor/nordic/nrf54l_05_10_15.dtsi:269 */
				bt_hci_sdc: bt_hci_sdc {
					compatible = "nordic,bt-hci-sdc"; /* in zephyr/dts/vendor/nordic/nrf54l_05_10_15.dtsi:270 */
					status = "okay";                  /* in zephyr/dts/arm/nordic/nrf54l_05_10_15_cpuapp.dtsi:45 */
				};

				/* node '/soc/peripheral@50000000/radio@8a000/bt_hci_controller' defined in zephyr/dts/vendor/nordic/nrf54l_05_10_15.dtsi:274 */
				bt_hci_controller: bt_hci_controller {
					compatible = "zephyr,bt-hci-ll-sw-split"; /* in zephyr/dts/vendor/nordic/nrf54l_05_10_15.dtsi:275 */
					status = "disabled";                      /* in zephyr/dts/vendor/nordic/nrf54l_05_10_15.dtsi:276 */
				};
			};

			/* node '/soc/peripheral@50000000/dppic@c2000' defined in zephyr/dts/vendor/nordic/nrf54l_05_10_15.dtsi:280 */
			dppic20: dppic@c2000 {
				compatible = "nordic,nrf-dppic"; /* in zephyr/dts/vendor/nordic/nrf54l_05_10_15.dtsi:281 */
				reg = < 0xc2000 0x808 >;         /* in zephyr/dts/vendor/nordic/nrf54l_05_10_15.dtsi:282 */
				channels = < 0x10 >;             /* in zephyr/dts/vendor/nordic/nrf54l_05_10_15.dtsi:284 */
				groups = < 0x6 >;                /* in zephyr/dts/vendor/nordic/nrf54l_05_10_15.dtsi:285 */
				status = "okay";                 /* in zephyr/dts/arm/nordic/nrf54l_05_10_15_cpuapp.dtsi:108 */
			};

			/* node '/soc/peripheral@50000000/ppib@c3000' defined in zephyr/dts/vendor/nordic/nrf54l_05_10_15.dtsi:288 */
			ppib20: ppib@c3000 {
				compatible = "nordic,nrf-ppib"; /* in zephyr/dts/vendor/nordic/nrf54l_05_10_15.dtsi:289 */
				reg = < 0xc3000 0x1000 >;       /* in zephyr/dts/vendor/nordic/nrf54l_05_10_15.dtsi:290 */
				channels = < 0x8 >;             /* in zephyr/dts/vendor/nordic/nrf54l_05_10_15.dtsi:292 */
				status = "okay";                /* in zephyr/dts/arm/nordic/nrf54l_05_10_15_cpuapp.dtsi:132 */
			};

			/* node '/soc/peripheral@50000000/ppib@c4000' defined in zephyr/dts/vendor/nordic/nrf54l_05_10_15.dtsi:295 */
			ppib21: ppib@c4000 {
				compatible = "nordic,nrf-ppib"; /* in zephyr/dts/vendor/nordic/nrf54l_05_10_15.dtsi:296 */
				reg = < 0xc4000 0x1000 >;       /* in zephyr/dts/vendor/nordic/nrf54l_05_10_15.dtsi:297 */
				channels = < 0x10 >;            /* in zephyr/dts/vendor/nordic/nrf54l_05_10_15.dtsi:299 */
				status = "okay";                /* in zephyr/dts/arm/nordic/nrf54l_05_10_15_cpuapp.dtsi:136 */
			};

			/* node '/soc/peripheral@50000000/ppib@c5000' defined in zephyr/dts/vendor/nordic/nrf54l_05_10_15.dtsi:302 */
			ppib22: ppib@c5000 {
				compatible = "nordic,nrf-ppib"; /* in zephyr/dts/vendor/nordic/nrf54l_05_10_15.dtsi:303 */
				reg = < 0xc5000 0x1000 >;       /* in zephyr/dts/vendor/nordic/nrf54l_05_10_15.dtsi:304 */
				channels = < 0x4 >;             /* in zephyr/dts/vendor/nordic/nrf54l_05_10_15.dtsi:306 */
				status = "okay";                /* in zephyr/dts/arm/nordic/nrf54l_05_10_15_cpuapp.dtsi:140 */
			};

			/* node '/soc/peripheral@50000000/i2c@c6000' defined in zephyr/dts/vendor/nordic/nrf54l_05_10_15.dtsi:309 */
			i2c20: i2c@c6000 {
				compatible = "nordic,nrf-twim";    /* in zephyr/dts/vendor/nordic/nrf54l_05_10_15.dtsi:310 */
				#address-cells = < 0x1 >;          /* in zephyr/dts/vendor/nordic/nrf54l_05_10_15.dtsi:311 */
				#size-cells = < 0x0 >;             /* in zephyr/dts/vendor/nordic/nrf54l_05_10_15.dtsi:312 */
				reg = < 0xc6000 0x1000 >;          /* in zephyr/dts/vendor/nordic/nrf54l_05_10_15.dtsi:313 */
				interrupts = < 0xc6 0x1 >;         /* in zephyr/dts/vendor/nordic/nrf54l_05_10_15.dtsi:314 */
				easydma-maxcnt-bits = < 0x10 >;    /* in zephyr/dts/vendor/nordic/nrf54l_05_10_15.dtsi:315 */
				clock-tolerance-percent = < 0x6 >; /* in zephyr/dts/vendor/nordic/nrf54l_05_10_15.dtsi:316 */
				status = "disabled";               /* in zephyr/dts/vendor/nordic/nrf54l_05_10_15.dtsi:317 */
				zephyr,pm-device-runtime-auto;     /* in zephyr/dts/vendor/nordic/nrf54l_05_10_15.dtsi:318 */
			};

			/* node '/soc/peripheral@50000000/spi@c6000' defined in zephyr/dts/vendor/nordic/nrf54l_05_10_15.dtsi:321 */
			spi20: spi@c6000 {
				compatible = "nordic,nrf-spim"; /* in zephyr/dts/vendor/nordic/nrf54l_05_10_15.dtsi:328 */
				#address-cells = < 0x1 >;       /* in zephyr/dts/vendor/nordic/nrf54l_05_10_15.dtsi:329 */
				#size-cells = < 0x0 >;          /* in zephyr/dts/vendor/nordic/nrf54l_05_10_15.dtsi:330 */
				reg = < 0xc6000 0x1000 >;       /* in zephyr/dts/vendor/nordic/nrf54l_05_10_15.dtsi:331 */
				interrupts = < 0xc6 0x1 >;      /* in zephyr/dts/vendor/nordic/nrf54l_05_10_15.dtsi:332 */
				max-frequency = < 0x7a1200 >;   /* in zephyr/dts/vendor/nordic/nrf54l_05_10_15.dtsi:333 */
				easydma-maxcnt-bits = < 0x10 >; /* in zephyr/dts/vendor/nordic/nrf54l_05_10_15.dtsi:334 */
				rx-delay-supported;             /* in zephyr/dts/vendor/nordic/nrf54l_05_10_15.dtsi:335 */
				rx-delay = < 0x1 >;             /* in zephyr/dts/vendor/nordic/nrf54l_05_10_15.dtsi:336 */
				status = "disabled";            /* in zephyr/dts/vendor/nordic/nrf54l_05_10_15.dtsi:337 */
			};

			/* node '/soc/peripheral@50000000/uart@c6000' defined in zephyr/dts/vendor/nordic/nrf54l_05_10_15.dtsi:340 */
			uart20: uart@c6000 {
				compatible = "nordic,nrf-uarte"; /* in zephyr/dts/vendor/nordic/nrf54l_05_10_15.dtsi:341 */
				reg = < 0xc6000 0x1000 >;        /* in zephyr/dts/vendor/nordic/nrf54l_05_10_15.dtsi:342 */
				interrupts = < 0xc6 0x1 >;       /* in zephyr/dts/vendor/nordic/nrf54l_05_10_15.dtsi:343 */
				endtx-stoptx-supported;          /* in zephyr/dts/vendor/nordic/nrf54l_05_10_15.dtsi:345 */
				frame-timeout-supported;         /* in zephyr/dts/vendor/nordic/nrf54l_05_10_15.dtsi:346 */
				current-speed = < 0x1c200 >;     /* in zephyr/boards/nordic/nrf54l15dk/nrf54l15dk_common.dtsi:113 */
				pinctrl-0 = < &uart20_default >; /* in zephyr/boards/nordic/nrf54l15dk/nrf54l15dk_common.dtsi:114 */
				pinctrl-1 = < &uart20_sleep >;   /* in zephyr/boards/nordic/nrf54l15dk/nrf54l15dk_common.dtsi:115 */
				pinctrl-names = "default",
				                "sleep";         /* in zephyr/boards/nordic/nrf54l15dk/nrf54l15dk_common.dtsi:116 */
				status = "okay";                 /* in zephyr/boards/nordic/nrf54l15dk/nrf54l_05_10_15_cpuapp_common.dtsi:61 */
			};

			/* node '/soc/peripheral@50000000/i2c@c7000' defined in zephyr/dts/vendor/nordic/nrf54l_05_10_15.dtsi:349 */
			i2c21: i2c@c7000 {
				compatible = "nordic,nrf-twim";    /* in zephyr/dts/vendor/nordic/nrf54l_05_10_15.dtsi:350 */
				#address-cells = < 0x1 >;          /* in zephyr/dts/vendor/nordic/nrf54l_05_10_15.dtsi:351 */
				#size-cells = < 0x0 >;             /* in zephyr/dts/vendor/nordic/nrf54l_05_10_15.dtsi:352 */
				reg = < 0xc7000 0x1000 >;          /* in zephyr/dts/vendor/nordic/nrf54l_05_10_15.dtsi:353 */
				interrupts = < 0xc7 0x1 >;         /* in zephyr/dts/vendor/nordic/nrf54l_05_10_15.dtsi:354 */
				easydma-maxcnt-bits = < 0x10 >;    /* in zephyr/dts/vendor/nordic/nrf54l_05_10_15.dtsi:355 */
				clock-tolerance-percent = < 0x6 >; /* in zephyr/dts/vendor/nordic/nrf54l_05_10_15.dtsi:356 */
				status = "disabled";               /* in zephyr/dts/vendor/nordic/nrf54l_05_10_15.dtsi:357 */
				zephyr,pm-device-runtime-auto;     /* in zephyr/dts/vendor/nordic/nrf54l_05_10_15.dtsi:358 */
			};

			/* node '/soc/peripheral@50000000/spi@c7000' defined in zephyr/dts/vendor/nordic/nrf54l_05_10_15.dtsi:361 */
			spi21: spi@c7000 {
				compatible = "nordic,nrf-spim"; /* in zephyr/dts/vendor/nordic/nrf54l_05_10_15.dtsi:368 */
				#address-cells = < 0x1 >;       /* in zephyr/dts/vendor/nordic/nrf54l_05_10_15.dtsi:369 */
				#size-cells = < 0x0 >;          /* in zephyr/dts/vendor/nordic/nrf54l_05_10_15.dtsi:370 */
				reg = < 0xc7000 0x1000 >;       /* in zephyr/dts/vendor/nordic/nrf54l_05_10_15.dtsi:371 */
				interrupts = < 0xc7 0x1 >;      /* in zephyr/dts/vendor/nordic/nrf54l_05_10_15.dtsi:372 */
				max-frequency = < 0x7a1200 >;   /* in zephyr/dts/vendor/nordic/nrf54l_05_10_15.dtsi:373 */
				easydma-maxcnt-bits = < 0x10 >; /* in zephyr/dts/vendor/nordic/nrf54l_05_10_15.dtsi:374 */
				rx-delay-supported;             /* in zephyr/dts/vendor/nordic/nrf54l_05_10_15.dtsi:375 */
				rx-delay = < 0x1 >;             /* in zephyr/dts/vendor/nordic/nrf54l_05_10_15.dtsi:376 */
				status = "disabled";            /* in zephyr/dts/vendor/nordic/nrf54l_05_10_15.dtsi:377 */
			};

			/* node '/soc/peripheral@50000000/uart@c7000' defined in zephyr/dts/vendor/nordic/nrf54l_05_10_15.dtsi:380 */
			uart21: uart@c7000 {
				compatible = "nordic,nrf-uarte"; /* in zephyr/dts/vendor/nordic/nrf54l_05_10_15.dtsi:381 */
				reg = < 0xc7000 0x1000 >;        /* in zephyr/dts/vendor/nordic/nrf54l_05_10_15.dtsi:382 */
				interrupts = < 0xc7 0x1 >;       /* in zephyr/dts/vendor/nordic/nrf54l_05_10_15.dtsi:383 */
				status = "disabled";             /* in zephyr/dts/vendor/nordic/nrf54l_05_10_15.dtsi:384 */
				endtx-stoptx-supported;          /* in zephyr/dts/vendor/nordic/nrf54l_05_10_15.dtsi:385 */
				frame-timeout-supported;         /* in zephyr/dts/vendor/nordic/nrf54l_05_10_15.dtsi:386 */
			};

			/* node '/soc/peripheral@50000000/i2c@c8000' defined in zephyr/dts/vendor/nordic/nrf54l_05_10_15.dtsi:389 */
			i2c22: i2c@c8000 {
				compatible = "nordic,nrf-twim";    /* in zephyr/dts/vendor/nordic/nrf54l_05_10_15.dtsi:390 */
				#address-cells = < 0x1 >;          /* in zephyr/dts/vendor/nordic/nrf54l_05_10_15.dtsi:391 */
				#size-cells = < 0x0 >;             /* in zephyr/dts/vendor/nordic/nrf54l_05_10_15.dtsi:392 */
				reg = < 0xc8000 0x1000 >;          /* in zephyr/dts/vendor/nordic/nrf54l_05_10_15.dtsi:393 */
				interrupts = < 0xc8 0x1 >;         /* in zephyr/dts/vendor/nordic/nrf54l_05_10_15.dtsi:394 */
				easydma-maxcnt-bits = < 0x10 >;    /* in zephyr/dts/vendor/nordic/nrf54l_05_10_15.dtsi:395 */
				clock-tolerance-percent = < 0x6 >; /* in zephyr/dts/vendor/nordic/nrf54l_05_10_15.dtsi:396 */
				status = "disabled";               /* in zephyr/dts/vendor/nordic/nrf54l_05_10_15.dtsi:397 */
				zephyr,pm-device-runtime-auto;     /* in zephyr/dts/vendor/nordic/nrf54l_05_10_15.dtsi:398 */
			};

			/* node '/soc/peripheral@50000000/spi@c8000' defined in zephyr/dts/vendor/nordic/nrf54l_05_10_15.dtsi:401 */
			spi22: nordic_expansion_spi: spi@c8000 {
				compatible = "nordic,nrf-spim"; /* in zephyr/dts/vendor/nordic/nrf54l_05_10_15.dtsi:408 */
				#address-cells = < 0x1 >;       /* in zephyr/dts/vendor/nordic/nrf54l_05_10_15.dtsi:409 */
				#size-cells = < 0x0 >;          /* in zephyr/dts/vendor/nordic/nrf54l_05_10_15.dtsi:410 */
				reg = < 0xc8000 0x1000 >;       /* in zephyr/dts/vendor/nordic/nrf54l_05_10_15.dtsi:411 */
				interrupts = < 0xc8 0x1 >;      /* in zephyr/dts/vendor/nordic/nrf54l_05_10_15.dtsi:412 */
				max-frequency = < 0x7a1200 >;   /* in zephyr/dts/vendor/nordic/nrf54l_05_10_15.dtsi:413 */
				easydma-maxcnt-bits = < 0x10 >; /* in zephyr/dts/vendor/nordic/nrf54l_05_10_15.dtsi:414 */
				rx-delay-supported;             /* in zephyr/dts/vendor/nordic/nrf54l_05_10_15.dtsi:415 */
				rx-delay = < 0x1 >;             /* in zephyr/dts/vendor/nordic/nrf54l_05_10_15.dtsi:416 */
				status = "disabled";            /* in zephyr/dts/vendor/nordic/nrf54l_05_10_15.dtsi:417 */
				cs-gpios = < &gpio1 0xa 0x1 >;  /* in zephyr/boards/nordic/nrf54l15dk/nrf54l_05_10_15_cpuapp_common.dtsi:148 */
				pinctrl-0 = < &spi22_default >; /* in zephyr/boards/nordic/nrf54l15dk/nrf54l_05_10_15_cpuapp_common.dtsi:149 */
				pinctrl-1 = < &spi22_sleep >;   /* in zephyr/boards/nordic/nrf54l15dk/nrf54l_05_10_15_cpuapp_common.dtsi:150 */
				pinctrl-names = "default",
				                "sleep";        /* in zephyr/boards/nordic/nrf54l15dk/nrf54l_05_10_15_cpuapp_common.dtsi:151 */
			};

			/* node '/soc/peripheral@50000000/uart@c8000' defined in zephyr/dts/vendor/nordic/nrf54l_05_10_15.dtsi:420 */
			uart22: uart@c8000 {
				compatible = "nordic,nrf-uarte"; /* in zephyr/dts/vendor/nordic/nrf54l_05_10_15.dtsi:421 */
				reg = < 0xc8000 0x1000 >;        /* in zephyr/dts/vendor/nordic/nrf54l_05_10_15.dtsi:422 */
				interrupts = < 0xc8 0x1 >;       /* in zephyr/dts/vendor/nordic/nrf54l_05_10_15.dtsi:423 */
				status = "disabled";             /* in zephyr/dts/vendor/nordic/nrf54l_05_10_15.dtsi:424 */
				endtx-stoptx-supported;          /* in zephyr/dts/vendor/nordic/nrf54l_05_10_15.dtsi:425 */
				frame-timeout-supported;         /* in zephyr/dts/vendor/nordic/nrf54l_05_10_15.dtsi:426 */
			};

			/* node '/soc/peripheral@50000000/egu@c9000' defined in zephyr/dts/vendor/nordic/nrf54l_05_10_15.dtsi:429 */
			egu20: egu@c9000 {
				compatible = "nordic,nrf-egu"; /* in zephyr/dts/vendor/nordic/nrf54l_05_10_15.dtsi:430 */
				reg = < 0xc9000 0x1000 >;      /* in zephyr/dts/vendor/nordic/nrf54l_05_10_15.dtsi:431 */
				interrupts = < 0xc9 0x1 >;     /* in zephyr/dts/vendor/nordic/nrf54l_05_10_15.dtsi:432 */
				status = "disabled";           /* in zephyr/dts/vendor/nordic/nrf54l_05_10_15.dtsi:433 */
			};

			/* node '/soc/peripheral@50000000/timer@ca000' defined in zephyr/dts/vendor/nordic/nrf54l_05_10_15.dtsi:436 */
			timer20: timer@ca000 {
				compatible = "nordic,nrf-timer"; /* in zephyr/dts/vendor/nordic/nrf54l_05_10_15.dtsi:437 */
				status = "disabled";             /* in zephyr/dts/vendor/nordic/nrf54l_05_10_15.dtsi:438 */
				reg = < 0xca000 0x1000 >;        /* in zephyr/dts/vendor/nordic/nrf54l_05_10_15.dtsi:439 */
				cc-num = < 0x6 >;                /* in zephyr/dts/vendor/nordic/nrf54l_05_10_15.dtsi:440 */
				max-bit-width = < 0x20 >;        /* in zephyr/dts/vendor/nordic/nrf54l_05_10_15.dtsi:441 */
				interrupts = < 0xca 0x1 >;       /* in zephyr/dts/vendor/nordic/nrf54l_05_10_15.dtsi:442 */
				prescaler = < 0x0 >;             /* in zephyr/dts/vendor/nordic/nrf54l_05_10_15.dtsi:443 */
			};

			/* node '/soc/peripheral@50000000/timer@cb000' defined in zephyr/dts/vendor/nordic/nrf54l_05_10_15.dtsi:446 */
			timer21: timer@cb000 {
				compatible = "nordic,nrf-timer"; /* in zephyr/dts/vendor/nordic/nrf54l_05_10_15.dtsi:447 */
				status = "disabled";             /* in zephyr/dts/vendor/nordic/nrf54l_05_10_15.dtsi:448 */
				reg = < 0xcb000 0x1000 >;        /* in zephyr/dts/vendor/nordic/nrf54l_05_10_15.dtsi:449 */
				cc-num = < 0x6 >;                /* in zephyr/dts/vendor/nordic/nrf54l_05_10_15.dtsi:450 */
				max-bit-width = < 0x20 >;        /* in zephyr/dts/vendor/nordic/nrf54l_05_10_15.dtsi:451 */
				interrupts = < 0xcb 0x1 >;       /* in zephyr/dts/vendor/nordic/nrf54l_05_10_15.dtsi:452 */
				prescaler = < 0x0 >;             /* in zephyr/dts/vendor/nordic/nrf54l_05_10_15.dtsi:453 */
			};

			/* node '/soc/peripheral@50000000/timer@cc000' defined in zephyr/dts/vendor/nordic/nrf54l_05_10_15.dtsi:456 */
			timer22: timer@cc000 {
				compatible = "nordic,nrf-timer"; /* in zephyr/dts/vendor/nordic/nrf54l_05_10_15.dtsi:457 */
				status = "disabled";             /* in zephyr/dts/vendor/nordic/nrf54l_05_10_15.dtsi:458 */
				reg = < 0xcc000 0x1000 >;        /* in zephyr/dts/vendor/nordic/nrf54l_05_10_15.dtsi:459 */
				cc-num = < 0x6 >;                /* in zephyr/dts/vendor/nordic/nrf54l_05_10_15.dtsi:460 */
				max-bit-width = < 0x20 >;        /* in zephyr/dts/vendor/nordic/nrf54l_05_10_15.dtsi:461 */
				interrupts = < 0xcc 0x1 >;       /* in zephyr/dts/vendor/nordic/nrf54l_05_10_15.dtsi:462 */
				prescaler = < 0x0 >;             /* in zephyr/dts/vendor/nordic/nrf54l_05_10_15.dtsi:463 */
			};

			/* node '/soc/peripheral@50000000/timer@cd000' defined in zephyr/dts/vendor/nordic/nrf54l_05_10_15.dtsi:466 */
			timer23: timer@cd000 {
				compatible = "nordic,nrf-timer"; /* in zephyr/dts/vendor/nordic/nrf54l_05_10_15.dtsi:467 */
				status = "disabled";             /* in zephyr/dts/vendor/nordic/nrf54l_05_10_15.dtsi:468 */
				reg = < 0xcd000 0x1000 >;        /* in zephyr/dts/vendor/nordic/nrf54l_05_10_15.dtsi:469 */
				cc-num = < 0x6 >;                /* in zephyr/dts/vendor/nordic/nrf54l_05_10_15.dtsi:470 */
				max-bit-width = < 0x20 >;        /* in zephyr/dts/vendor/nordic/nrf54l_05_10_15.dtsi:471 */
				interrupts = < 0xcd 0x1 >;       /* in zephyr/dts/vendor/nordic/nrf54l_05_10_15.dtsi:472 */
				prescaler = < 0x0 >;             /* in zephyr/dts/vendor/nordic/nrf54l_05_10_15.dtsi:473 */
			};

			/* node '/soc/peripheral@50000000/timer@ce000' defined in zephyr/dts/vendor/nordic/nrf54l_05_10_15.dtsi:476 */
			timer24: timer@ce000 {
				compatible = "nordic,nrf-timer"; /* in zephyr/dts/vendor/nordic/nrf54l_05_10_15.dtsi:477 */
				status = "disabled";             /* in zephyr/dts/vendor/nordic/nrf54l_05_10_15.dtsi:478 */
				reg = < 0xce000 0x1000 >;        /* in zephyr/dts/vendor/nordic/nrf54l_05_10_15.dtsi:479 */
				cc-num = < 0x6 >;                /* in zephyr/dts/vendor/nordic/nrf54l_05_10_15.dtsi:480 */
				max-bit-width = < 0x20 >;        /* in zephyr/dts/vendor/nordic/nrf54l_05_10_15.dtsi:481 */
				interrupts = < 0xce 0x1 >;       /* in zephyr/dts/vendor/nordic/nrf54l_05_10_15.dtsi:482 */
				prescaler = < 0x0 >;             /* in zephyr/dts/vendor/nordic/nrf54l_05_10_15.dtsi:483 */
			};

			/* node '/soc/peripheral@50000000/pdm@d0000' defined in zephyr/dts/vendor/nordic/nrf54l_05_10_15.dtsi:486 */
			pdm20: pdm@d0000 {
				compatible = "nordic,nrf-pdm"; /* in zephyr/dts/vendor/nordic/nrf54l_05_10_15.dtsi:487 */
				status = "disabled";           /* in zephyr/dts/vendor/nordic/nrf54l_05_10_15.dtsi:488 */
				reg = < 0xd0000 0x1000 >;      /* in zephyr/dts/vendor/nordic/nrf54l_05_10_15.dtsi:489 */
				interrupts = < 0xd0 0x1 >;     /* in zephyr/dts/vendor/nordic/nrf54l_05_10_15.dtsi:490 */
			};

			/* node '/soc/peripheral@50000000/pdm@d1000' defined in zephyr/dts/vendor/nordic/nrf54l_05_10_15.dtsi:493 */
			pdm21: pdm@d1000 {
				compatible = "nordic,nrf-pdm"; /* in zephyr/dts/vendor/nordic/nrf54l_05_10_15.dtsi:494 */
				status = "disabled";           /* in zephyr/dts/vendor/nordic/nrf54l_05_10_15.dtsi:495 */
				reg = < 0xd1000 0x1000 >;      /* in zephyr/dts/vendor/nordic/nrf54l_05_10_15.dtsi:496 */
				interrupts = < 0xd1 0x1 >;     /* in zephyr/dts/vendor/nordic/nrf54l_05_10_15.dtsi:497 */
			};

			/* node '/soc/peripheral@50000000/pwm@d2000' defined in zephyr/dts/vendor/nordic/nrf54l_05_10_15.dtsi:500 */
			pwm20: pwm@d2000 {
				compatible = "nordic,nrf-pwm";  /* in zephyr/dts/vendor/nordic/nrf54l_05_10_15.dtsi:501 */
				reg = < 0xd2000 0x1000 >;       /* in zephyr/dts/vendor/nordic/nrf54l_05_10_15.dtsi:503 */
				interrupts = < 0xd2 0x1 >;      /* in zephyr/dts/vendor/nordic/nrf54l_05_10_15.dtsi:504 */
				#pwm-cells = < 0x3 >;           /* in zephyr/dts/vendor/nordic/nrf54l_05_10_15.dtsi:505 */
				idleout-supported;              /* in zephyr/dts/vendor/nordic/nrf54l_05_10_15.dtsi:506 */
				status = "okay";                /* in zephyr/boards/nordic/nrf54l15dk/nrf54l15dk_common.dtsi:127 */
				pinctrl-0 = < &pwm20_default >; /* in zephyr/boards/nordic/nrf54l15dk/nrf54l15dk_common.dtsi:128 */
				pinctrl-1 = < &pwm20_sleep >;   /* in zephyr/boards/nordic/nrf54l15dk/nrf54l15dk_common.dtsi:129 */
				pinctrl-names = "default",
				                "sleep";        /* in zephyr/boards/nordic/nrf54l15dk/nrf54l15dk_common.dtsi:130 */
				phandle = < 0x14 >;             /* in zephyr/boards/nordic/nrf54l15dk/nrf54l15dk_common.dtsi:44 */
			};

			/* node '/soc/peripheral@50000000/pwm@d3000' defined in zephyr/dts/vendor/nordic/nrf54l_05_10_15.dtsi:509 */
			pwm21: pwm@d3000 {
				compatible = "nordic,nrf-pwm"; /* in zephyr/dts/vendor/nordic/nrf54l_05_10_15.dtsi:510 */
				status = "disabled";           /* in zephyr/dts/vendor/nordic/nrf54l_05_10_15.dtsi:511 */
				reg = < 0xd3000 0x1000 >;      /* in zephyr/dts/vendor/nordic/nrf54l_05_10_15.dtsi:512 */
				interrupts = < 0xd3 0x1 >;     /* in zephyr/dts/vendor/nordic/nrf54l_05_10_15.dtsi:513 */
				#pwm-cells = < 0x3 >;          /* in zephyr/dts/vendor/nordic/nrf54l_05_10_15.dtsi:514 */
				idleout-supported;             /* in zephyr/dts/vendor/nordic/nrf54l_05_10_15.dtsi:515 */
			};

			/* node '/soc/peripheral@50000000/pwm@d4000' defined in zephyr/dts/vendor/nordic/nrf54l_05_10_15.dtsi:518 */
			pwm22: pwm@d4000 {
				compatible = "nordic,nrf-pwm"; /* in zephyr/dts/vendor/nordic/nrf54l_05_10_15.dtsi:519 */
				status = "disabled";           /* in zephyr/dts/vendor/nordic/nrf54l_05_10_15.dtsi:520 */
				reg = < 0xd4000 0x1000 >;      /* in zephyr/dts/vendor/nordic/nrf54l_05_10_15.dtsi:521 */
				interrupts = < 0xd4 0x1 >;     /* in zephyr/dts/vendor/nordic/nrf54l_05_10_15.dtsi:522 */
				#pwm-cells = < 0x3 >;          /* in zephyr/dts/vendor/nordic/nrf54l_05_10_15.dtsi:523 */
				idleout-supported;             /* in zephyr/dts/vendor/nordic/nrf54l_05_10_15.dtsi:524 */
			};

			/* node '/soc/peripheral@50000000/adc@d5000' defined in zephyr/dts/vendor/nordic/nrf54l_05_10_15.dtsi:527 */
			adc: adc@d5000 {
				compatible = "nordic,nrf-saadc"; /* in zephyr/dts/vendor/nordic/nrf54l_05_10_15.dtsi:528 */
				reg = < 0xd5000 0x1000 >;        /* in zephyr/dts/vendor/nordic/nrf54l_05_10_15.dtsi:529 */
				interrupts = < 0xd5 0x1 >;       /* in zephyr/dts/vendor/nordic/nrf54l_05_10_15.dtsi:530 */
				#io-channel-cells = < 0x1 >;     /* in zephyr/dts/vendor/nordic/nrf54l_05_10_15.dtsi:532 */
				zephyr,pm-device-runtime-auto;   /* in zephyr/dts/vendor/nordic/nrf54l_05_10_15.dtsi:533 */
				status = "okay";                 /* in zephyr/boards/nordic/nrf54l15dk/nrf54l_05_10_15_cpuapp_common.dtsi:140 */
			};

			/* node '/soc/peripheral@50000000/nfct@d6000' defined in zephyr/dts/vendor/nordic/nrf54l_05_10_15.dtsi:536 */
			nfct: nfct@d6000 {
				compatible = "nordic,nrf-nfct"; /* in zephyr/dts/vendor/nordic/nrf54l_05_10_15.dtsi:537 */
				reg = < 0xd6000 0x1000 >;       /* in zephyr/dts/vendor/nordic/nrf54l_05_10_15.dtsi:538 */
				interrupts = < 0xd6 0x1 >;      /* in zephyr/dts/vendor/nordic/nrf54l_05_10_15.dtsi:539 */
				status = "okay";                /* in zephyr/boards/nordic/nrf54l15dk/nrf54l_05_10_15_cpuapp_common.dtsi:65 */
			};

			/* node '/soc/peripheral@50000000/temp@d7000' defined in zephyr/dts/vendor/nordic/nrf54l_05_10_15.dtsi:543 */
			temp: temp@d7000 {
				compatible = "nordic,nrf-temp"; /* in zephyr/dts/vendor/nordic/nrf54l_05_10_15.dtsi:544 */
				reg = < 0xd7000 0x1000 >;       /* in zephyr/dts/vendor/nordic/nrf54l_05_10_15.dtsi:545 */
				interrupts = < 0xd7 0x1 >;      /* in zephyr/dts/vendor/nordic/nrf54l_05_10_15.dtsi:546 */
				status = "okay";                /* in zephyr/boards/nordic/nrf54l15dk/nrf54l_05_10_15_cpuapp_common.dtsi:97 */
			};

			/* node '/soc/peripheral@50000000/gpio@d8200' defined in zephyr/dts/vendor/nordic/nrf54l_05_10_15.dtsi:550 */
			gpio1: gpio@d8200 {
				compatible = "nordic,nrf-gpio";  /* in zephyr/dts/vendor/nordic/nrf54l_05_10_15.dtsi:551 */
				gpio-controller;                 /* in zephyr/dts/vendor/nordic/nrf54l_05_10_15.dtsi:552 */
				reg = < 0xd8200 0x300 >;         /* in zephyr/dts/vendor/nordic/nrf54l_05_10_15.dtsi:553 */
				#gpio-cells = < 0x2 >;           /* in zephyr/dts/vendor/nordic/nrf54l_05_10_15.dtsi:554 */
				ngpios = < 0x10 >;               /* in zephyr/dts/vendor/nordic/nrf54l_05_10_15.dtsi:555 */
				port = < 0x1 >;                  /* in zephyr/dts/vendor/nordic/nrf54l_05_10_15.dtsi:557 */
				gpiote-instance = < &gpiote20 >; /* in zephyr/dts/vendor/nordic/nrf54l_05_10_15.dtsi:558 */
				status = "okay";                 /* in zephyr/boards/nordic/nrf54l15dk/nrf54l_05_10_15_cpuapp_common.dtsi:73 */
				phandle = < 0x9 >;               /* in zephyr/boards/nordic/nrf54l15dk/nrf54l_05_10_15_cpuapp_common.dtsi:148 */
			};

			/* node '/soc/peripheral@50000000/gpiote@da000' defined in zephyr/dts/vendor/nordic/nrf54l_05_10_15.dtsi:561 */
			gpiote20: gpiote@da000 {
				compatible = "nordic,nrf-gpiote"; /* in zephyr/dts/vendor/nordic/nrf54l_05_10_15.dtsi:562 */
				reg = < 0xda000 0x1000 >;         /* in zephyr/dts/vendor/nordic/nrf54l_05_10_15.dtsi:563 */
				instance = < 0x14 >;              /* in zephyr/dts/vendor/nordic/nrf54l_05_10_15.dtsi:565 */
				interrupts = < 0xdb 0x1 >;        /* in zephyr/dts/arm/nordic/nrf54l_05_10_15_cpuapp.dtsi:87 */
				status = "okay";                  /* in zephyr/boards/nordic/nrf54l15dk/nrf54l_05_10_15_cpuapp_common.dtsi:81 */
				phandle = < 0xe >;                /* in zephyr/dts/vendor/nordic/nrf54l_05_10_15.dtsi:558 */
			};

			/* node '/soc/peripheral@50000000/i2s@dd000' defined in zephyr/dts/vendor/nordic/nrf54l_05_10_15.dtsi:568 */
			i2s20: i2s@dd000 {
				compatible = "nordic,nrf-i2s"; /* in zephyr/dts/vendor/nordic/nrf54l_05_10_15.dtsi:569 */
				#address-cells = < 0x1 >;      /* in zephyr/dts/vendor/nordic/nrf54l_05_10_15.dtsi:570 */
				#size-cells = < 0x0 >;         /* in zephyr/dts/vendor/nordic/nrf54l_05_10_15.dtsi:571 */
				reg = < 0xdd000 0x1000 >;      /* in zephyr/dts/vendor/nordic/nrf54l_05_10_15.dtsi:572 */
				interrupts = < 0xdd 0x1 >;     /* in zephyr/dts/vendor/nordic/nrf54l_05_10_15.dtsi:573 */
				status = "disabled";           /* in zephyr/dts/vendor/nordic/nrf54l_05_10_15.dtsi:574 */
			};

			/* node '/soc/peripheral@50000000/qdec@e0000' defined in zephyr/dts/vendor/nordic/nrf54l_05_10_15.dtsi:577 */
			qdec20: qdec@e0000 {
				compatible = "nordic,nrf-qdec"; /* in zephyr/dts/vendor/nordic/nrf54l_05_10_15.dtsi:578 */
				reg = < 0xe0000 0x1000 >;       /* in zephyr/dts/vendor/nordic/nrf54l_05_10_15.dtsi:579 */
				interrupts = < 0xe0 0x1 >;      /* in zephyr/dts/vendor/nordic/nrf54l_05_10_15.dtsi:580 */
				status = "disabled";            /* in zephyr/dts/vendor/nordic/nrf54l_05_10_15.dtsi:581 */
			};

			/* node '/soc/peripheral@50000000/qdec@e1000' defined in zephyr/dts/vendor/nordic/nrf54l_05_10_15.dtsi:584 */
			qdec21: qdec@e1000 {
				compatible = "nordic,nrf-qdec"; /* in zephyr/dts/vendor/nordic/nrf54l_05_10_15.dtsi:585 */
				reg = < 0xe1000 0x1000 >;       /* in zephyr/dts/vendor/nordic/nrf54l_05_10_15.dtsi:586 */
				interrupts = < 0xe1 0x1 >;      /* in zephyr/dts/vendor/nordic/nrf54l_05_10_15.dtsi:587 */
				status = "disabled";            /* in zephyr/dts/vendor/nordic/nrf54l_05_10_15.dtsi:588 */
			};

			/* node '/soc/peripheral@50000000/grtc@e2000' defined in zephyr/dts/vendor/nordic/nrf54l_05_10_15.dtsi:591 */
			grtc: grtc@e2000 {
				compatible = "nordic,nrf-grtc";                                       /* in zephyr/dts/vendor/nordic/nrf54l_05_10_15.dtsi:592 */
				reg = < 0xe2000 0x1000 >;                                             /* in zephyr/dts/vendor/nordic/nrf54l_05_10_15.dtsi:593 */
				cc-num = < 0xc >;                                                     /* in zephyr/dts/vendor/nordic/nrf54l_05_10_15.dtsi:594 */
				clocks = < &lfxo >,
				         < &pclk >;                                                   /* in zephyr/dts/vendor/nordic/nrf54l_05_10_15.dtsi:595 */
				clock-names = "lfclock",
				              "hfclock";                                              /* in zephyr/dts/vendor/nordic/nrf54l_05_10_15.dtsi:596 */
				extended-channels = < 0x0 >;                                          /* in zephyr/dts/vendor/nordic/nrf54l_05_10_15.dtsi:598 */
				interrupts = < 0xe4 0x1 >,
				             < 0xe5 0x1 >;                                            /* in zephyr/dts/arm/nordic/nrf54l_05_10_15_cpuapp.dtsi:78 */
				owned-channels = < 0x0 0x1 0x2 0x3 0x4 0x5 0x6 0x7 0x8 0x9 0xa 0xb >; /* in zephyr/boards/nordic/nrf54l15dk/nrf54l_05_10_15_cpuapp_common.dtsi:54 */
				child-owned-channels = < 0x3 0x4 0x7 0x8 0x9 0xa 0xb >;               /* in zephyr/boards/nordic/nrf54l15dk/nrf54l_05_10_15_cpuapp_common.dtsi:56 */
				status = "okay";                                                      /* in zephyr/boards/nordic/nrf54l15dk/nrf54l_05_10_15_cpuapp_common.dtsi:57 */
			};

			/* node '/soc/peripheral@50000000/dppic@102000' defined in zephyr/dts/vendor/nordic/nrf54l_05_10_15.dtsi:601 */
			dppic30: dppic@102000 {
				compatible = "nordic,nrf-dppic"; /* in zephyr/dts/vendor/nordic/nrf54l_05_10_15.dtsi:602 */
				reg = < 0x102000 0x808 >;        /* in zephyr/dts/vendor/nordic/nrf54l_05_10_15.dtsi:603 */
				channels = < 0x4 >;              /* in zephyr/dts/vendor/nordic/nrf54l_05_10_15.dtsi:605 */
				groups = < 0x2 >;                /* in zephyr/dts/vendor/nordic/nrf54l_05_10_15.dtsi:606 */
				status = "okay";                 /* in zephyr/dts/arm/nordic/nrf54l_05_10_15_cpuapp.dtsi:112 */
			};

			/* node '/soc/peripheral@50000000/ppib@103000' defined in zephyr/dts/vendor/nordic/nrf54l_05_10_15.dtsi:609 */
			ppib30: ppib@103000 {
				compatible = "nordic,nrf-ppib"; /* in zephyr/dts/vendor/nordic/nrf54l_05_10_15.dtsi:610 */
				reg = < 0x103000 0x1000 >;      /* in zephyr/dts/vendor/nordic/nrf54l_05_10_15.dtsi:611 */
				channels = < 0x4 >;             /* in zephyr/dts/vendor/nordic/nrf54l_05_10_15.dtsi:613 */
				status = "okay";                /* in zephyr/dts/arm/nordic/nrf54l_05_10_15_cpuapp.dtsi:144 */
			};

			/* node '/soc/peripheral@50000000/i2c@104000' defined in zephyr/dts/vendor/nordic/nrf54l_05_10_15.dtsi:616 */
			i2c30: i2c@104000 {
				compatible = "nordic,nrf-twim";    /* in zephyr/dts/vendor/nordic/nrf54l_05_10_15.dtsi:617 */
				#address-cells = < 0x1 >;          /* in zephyr/dts/vendor/nordic/nrf54l_05_10_15.dtsi:618 */
				#size-cells = < 0x0 >;             /* in zephyr/dts/vendor/nordic/nrf54l_05_10_15.dtsi:619 */
				reg = < 0x104000 0x1000 >;         /* in zephyr/dts/vendor/nordic/nrf54l_05_10_15.dtsi:620 */
				interrupts = < 0x104 0x1 >;        /* in zephyr/dts/vendor/nordic/nrf54l_05_10_15.dtsi:621 */
				easydma-maxcnt-bits = < 0x10 >;    /* in zephyr/dts/vendor/nordic/nrf54l_05_10_15.dtsi:622 */
				clock-tolerance-percent = < 0x6 >; /* in zephyr/dts/vendor/nordic/nrf54l_05_10_15.dtsi:623 */
				status = "disabled";               /* in zephyr/dts/vendor/nordic/nrf54l_05_10_15.dtsi:624 */
				zephyr,pm-device-runtime-auto;     /* in zephyr/dts/vendor/nordic/nrf54l_05_10_15.dtsi:625 */
			};

			/* node '/soc/peripheral@50000000/spi@104000' defined in zephyr/dts/vendor/nordic/nrf54l_05_10_15.dtsi:628 */
			spi30: spi@104000 {
				compatible = "nordic,nrf-spim"; /* in zephyr/dts/vendor/nordic/nrf54l_05_10_15.dtsi:635 */
				#address-cells = < 0x1 >;       /* in zephyr/dts/vendor/nordic/nrf54l_05_10_15.dtsi:636 */
				#size-cells = < 0x0 >;          /* in zephyr/dts/vendor/nordic/nrf54l_05_10_15.dtsi:637 */
				reg = < 0x104000 0x1000 >;      /* in zephyr/dts/vendor/nordic/nrf54l_05_10_15.dtsi:638 */
				interrupts = < 0x104 0x1 >;     /* in zephyr/dts/vendor/nordic/nrf54l_05_10_15.dtsi:639 */
				max-frequency = < 0x7a1200 >;   /* in zephyr/dts/vendor/nordic/nrf54l_05_10_15.dtsi:640 */
				easydma-maxcnt-bits = < 0x10 >; /* in zephyr/dts/vendor/nordic/nrf54l_05_10_15.dtsi:641 */
				rx-delay-supported;             /* in zephyr/dts/vendor/nordic/nrf54l_05_10_15.dtsi:642 */
				rx-delay = < 0x1 >;             /* in zephyr/dts/vendor/nordic/nrf54l_05_10_15.dtsi:643 */
				status = "disabled";            /* in zephyr/dts/vendor/nordic/nrf54l_05_10_15.dtsi:644 */
			};

			/* node '/soc/peripheral@50000000/uart@104000' defined in zephyr/dts/vendor/nordic/nrf54l_05_10_15.dtsi:647 */
			uart30: uart@104000 {
				compatible = "nordic,nrf-uarte"; /* in zephyr/dts/vendor/nordic/nrf54l_05_10_15.dtsi:648 */
				reg = < 0x104000 0x1000 >;       /* in zephyr/dts/vendor/nordic/nrf54l_05_10_15.dtsi:649 */
				interrupts = < 0x104 0x1 >;      /* in zephyr/dts/vendor/nordic/nrf54l_05_10_15.dtsi:650 */
				status = "disabled";             /* in zephyr/dts/vendor/nordic/nrf54l_05_10_15.dtsi:651 */
				endtx-stoptx-supported;          /* in zephyr/dts/vendor/nordic/nrf54l_05_10_15.dtsi:652 */
				frame-timeout-supported;         /* in zephyr/dts/vendor/nordic/nrf54l_05_10_15.dtsi:653 */
				current-speed = < 0x1c200 >;     /* in zephyr/boards/nordic/nrf54l15dk/nrf54l15dk_common.dtsi:120 */
				pinctrl-0 = < &uart30_default >; /* in zephyr/boards/nordic/nrf54l15dk/nrf54l15dk_common.dtsi:121 */
				pinctrl-1 = < &uart30_sleep >;   /* in zephyr/boards/nordic/nrf54l15dk/nrf54l15dk_common.dtsi:122 */
				pinctrl-names = "default",
				                "sleep";         /* in zephyr/boards/nordic/nrf54l15dk/nrf54l15dk_common.dtsi:123 */
			};

			/* node '/soc/peripheral@50000000/clock@10e000' defined in zephyr/dts/vendor/nordic/nrf54l_05_10_15.dtsi:656 */
			clock: clock@10e000 {
				compatible = "nordic,nrf-clock"; /* in zephyr/dts/vendor/nordic/nrf54l_05_10_15.dtsi:657 */
				reg = < 0x10e000 0x1000 >;       /* in zephyr/dts/vendor/nordic/nrf54l_05_10_15.dtsi:658 */
				interrupts = < 0x105 0x1 >;      /* in zephyr/dts/vendor/nordic/nrf54l_05_10_15.dtsi:659 */
				status = "okay";                 /* in zephyr/boards/nordic/nrf54l15dk/nrf54l_05_10_15_cpuapp_common.dtsi:101 */
			};

			/* node '/soc/peripheral@50000000/power@10e000' defined in zephyr/dts/vendor/nordic/nrf54l_05_10_15.dtsi:663 */
			power: power@10e000 {
				compatible = "nordic,nrf-power";  /* in zephyr/dts/vendor/nordic/nrf54l_05_10_15.dtsi:664 */
				reg = < 0x10e000 0x1000 >;        /* in zephyr/dts/vendor/nordic/nrf54l_05_10_15.dtsi:665 */
				ranges = < 0x0 0x10e000 0x1000 >; /* in zephyr/dts/vendor/nordic/nrf54l_05_10_15.dtsi:666 */
				interrupts = < 0x105 0x1 >;       /* in zephyr/dts/vendor/nordic/nrf54l_05_10_15.dtsi:667 */
				status = "disabled";              /* in zephyr/dts/vendor/nordic/nrf54l_05_10_15.dtsi:668 */
				#address-cells = < 0x1 >;         /* in zephyr/dts/vendor/nordic/nrf54l_05_10_15.dtsi:669 */
				#size-cells = < 0x1 >;            /* in zephyr/dts/vendor/nordic/nrf54l_05_10_15.dtsi:670 */

				/* node '/soc/peripheral@50000000/power@10e000/gpregret1@500' defined in zephyr/dts/vendor/nordic/nrf54l_05_10_15.dtsi:672 */
				gpregret1: gpregret1@500 {
					#address-cells = < 0x1 >;           /* in zephyr/dts/vendor/nordic/nrf54l_05_10_15.dtsi:673 */
					#size-cells = < 0x1 >;              /* in zephyr/dts/vendor/nordic/nrf54l_05_10_15.dtsi:674 */
					compatible = "nordic,nrf-gpregret"; /* in zephyr/dts/vendor/nordic/nrf54l_05_10_15.dtsi:675 */
					reg = < 0x500 0x1 >;                /* in zephyr/dts/vendor/nordic/nrf54l_05_10_15.dtsi:676 */
					status = "okay";                    /* in zephyr/boards/nordic/nrf54l15dk/nrf54l_05_10_15_cpuapp_common.dtsi:105 */

					/* node '/soc/peripheral@50000000/power@10e000/gpregret1@500/boot_mode@0' defined in zephyr/boards/nordic/nrf54l15dk/nrf54l_05_10_15_cpuapp_common.dtsi:107 */
					boot_mode0: boot_mode@0 {
						compatible = "zephyr,retention"; /* in zephyr/boards/nordic/nrf54l15dk/nrf54l_05_10_15_cpuapp_common.dtsi:108 */
						status = "okay";                 /* in zephyr/boards/nordic/nrf54l15dk/nrf54l_05_10_15_cpuapp_common.dtsi:109 */
						reg = < 0x0 0x1 >;               /* in zephyr/boards/nordic/nrf54l15dk/nrf54l_05_10_15_cpuapp_common.dtsi:110 */
					};
				};

				/* node '/soc/peripheral@50000000/power@10e000/gpregret2@504' defined in zephyr/dts/vendor/nordic/nrf54l_05_10_15.dtsi:680 */
				gpregret2: gpregret2@504 {
					#address-cells = < 0x1 >;           /* in zephyr/dts/vendor/nordic/nrf54l_05_10_15.dtsi:681 */
					#size-cells = < 0x1 >;              /* in zephyr/dts/vendor/nordic/nrf54l_05_10_15.dtsi:682 */
					compatible = "nordic,nrf-gpregret"; /* in zephyr/dts/vendor/nordic/nrf54l_05_10_15.dtsi:683 */
					reg = < 0x504 0x1 >;                /* in zephyr/dts/vendor/nordic/nrf54l_05_10_15.dtsi:684 */
					status = "disabled";                /* in zephyr/dts/vendor/nordic/nrf54l_05_10_15.dtsi:685 */
				};
			};

			/* node '/soc/peripheral@50000000/comparator@106000' defined in zephyr/dts/vendor/nordic/nrf54l_05_10_15.dtsi:689 */
			comp: comparator@106000 {
				compatible = "nordic,nrf-comp"; /* in zephyr/dts/vendor/nordic/nrf54l_05_10_15.dtsi:694 */
				reg = < 0x106000 0x1000 >;      /* in zephyr/dts/vendor/nordic/nrf54l_05_10_15.dtsi:695 */
				status = "disabled";            /* in zephyr/dts/vendor/nordic/nrf54l_05_10_15.dtsi:696 */
				interrupts = < 0x106 0x1 >;     /* in zephyr/dts/vendor/nordic/nrf54l_05_10_15.dtsi:697 */
			};

			/* node '/soc/peripheral@50000000/watchdog@108000' defined in zephyr/dts/vendor/nordic/nrf54l_05_10_15.dtsi:703 */
			wdt30: watchdog@108000 {
				compatible = "nordic,nrf-wdt"; /* in zephyr/dts/vendor/nordic/nrf54l_05_10_15.dtsi:704 */
				reg = < 0x108000 0x620 >;      /* in zephyr/dts/vendor/nordic/nrf54l_05_10_15.dtsi:705 */
				interrupts = < 0x108 0x1 >;    /* in zephyr/dts/vendor/nordic/nrf54l_05_10_15.dtsi:706 */
				status = "disabled";           /* in zephyr/dts/vendor/nordic/nrf54l_05_10_15.dtsi:707 */
			};

			/* node '/soc/peripheral@50000000/watchdog@109000' defined in zephyr/dts/vendor/nordic/nrf54l_05_10_15.dtsi:711 */
			wdt31: watchdog@109000 {
				compatible = "nordic,nrf-wdt"; /* in zephyr/dts/vendor/nordic/nrf54l_05_10_15.dtsi:712 */
				reg = < 0x109000 0x620 >;      /* in zephyr/dts/vendor/nordic/nrf54l_05_10_15.dtsi:713 */
				interrupts = < 0x109 0x1 >;    /* in zephyr/dts/vendor/nordic/nrf54l_05_10_15.dtsi:714 */
				status = "disabled";           /* in zephyr/dts/vendor/nordic/nrf54l_05_10_15.dtsi:715 */
			};

			/* node '/soc/peripheral@50000000/gpio@10a000' defined in zephyr/dts/vendor/nordic/nrf54l_05_10_15.dtsi:718 */
			gpio0: gpio@10a000 {
				compatible = "nordic,nrf-gpio";  /* in zephyr/dts/vendor/nordic/nrf54l_05_10_15.dtsi:719 */
				gpio-controller;                 /* in zephyr/dts/vendor/nordic/nrf54l_05_10_15.dtsi:720 */
				reg = < 0x10a000 0x300 >;        /* in zephyr/dts/vendor/nordic/nrf54l_05_10_15.dtsi:721 */
				#gpio-cells = < 0x2 >;           /* in zephyr/dts/vendor/nordic/nrf54l_05_10_15.dtsi:722 */
				ngpios = < 0x7 >;                /* in zephyr/dts/vendor/nordic/nrf54l_05_10_15.dtsi:723 */
				port = < 0x0 >;                  /* in zephyr/dts/vendor/nordic/nrf54l_05_10_15.dtsi:725 */
				gpiote-instance = < &gpiote30 >; /* in zephyr/dts/vendor/nordic/nrf54l_05_10_15.dtsi:726 */
				status = "okay";                 /* in zephyr/boards/nordic/nrf54l15dk/nrf54l_05_10_15_cpuapp_common.dtsi:69 */
				phandle = < 0x15 >;              /* in zephyr/boards/nordic/nrf54l15dk/nrf54l15dk_common.dtsi:70 */
			};

			/* node '/soc/peripheral@50000000/gpiote@10c000' defined in zephyr/dts/vendor/nordic/nrf54l_05_10_15.dtsi:729 */
			gpiote30: gpiote@10c000 {
				compatible = "nordic,nrf-gpiote"; /* in zephyr/dts/vendor/nordic/nrf54l_05_10_15.dtsi:730 */
				reg = < 0x10c000 0x1000 >;        /* in zephyr/dts/vendor/nordic/nrf54l_05_10_15.dtsi:731 */
				instance = < 0x1e >;              /* in zephyr/dts/vendor/nordic/nrf54l_05_10_15.dtsi:733 */
				interrupts = < 0x10d 0x1 >;       /* in zephyr/dts/arm/nordic/nrf54l_05_10_15_cpuapp.dtsi:95 */
				status = "okay";                  /* in zephyr/boards/nordic/nrf54l15dk/nrf54l_05_10_15_cpuapp_common.dtsi:85 */
				phandle = < 0x13 >;               /* in zephyr/dts/vendor/nordic/nrf54l_05_10_15.dtsi:726 */
			};

			/* node '/soc/peripheral@50000000/regulator@120000' defined in zephyr/dts/vendor/nordic/nrf54l_05_10_15.dtsi:736 */
			regulators: regulator@120000 {
				compatible = "nordic,nrf54l-regulators"; /* in zephyr/dts/vendor/nordic/nrf54l_05_10_15.dtsi:737 */
				reg = < 0x120000 0x1000 >;               /* in zephyr/dts/vendor/nordic/nrf54l_05_10_15.dtsi:738 */
				#address-cells = < 0x1 >;                /* in zephyr/dts/vendor/nordic/nrf54l_05_10_15.dtsi:740 */
				#size-cells = < 0x1 >;                   /* in zephyr/dts/vendor/nordic/nrf54l_05_10_15.dtsi:741 */
				status = "okay";                         /* in zephyr/boards/nordic/nrf54l15dk/nrf54l_05_10_15_cpuapp_common.dtsi:45 */

				/* node '/soc/peripheral@50000000/regulator@120000/regulator@120600' defined in zephyr/dts/vendor/nordic/nrf54l_05_10_15.dtsi:743 */
				vregmain: regulator@120600 {
					compatible = "nordic,nrf5x-regulator"; /* in zephyr/dts/vendor/nordic/nrf54l_05_10_15.dtsi:744 */
					reg = < 0x120600 0x1 >;                /* in zephyr/dts/vendor/nordic/nrf54l_05_10_15.dtsi:745 */
					regulator-name = "VREGMAIN";           /* in zephyr/dts/vendor/nordic/nrf54l_05_10_15.dtsi:747 */
					status = "okay";                       /* in zephyr/boards/nordic/nrf54l15dk/nrf54l_05_10_15_cpuapp_common.dtsi:49 */
					regulator-initial-mode = < 0x1 >;      /* in zephyr/boards/nordic/nrf54l15dk/nrf54l_05_10_15_cpuapp_common.dtsi:50 */
				};
			};
		};

		/* node '/soc/rram-controller@5004b000' defined in zephyr/dts/vendor/nordic/nrf54l_05_10_15.dtsi:753 */
		rram_controller: rram-controller@5004b000 {
			compatible = "nordic,rram-controller"; /* in zephyr/dts/vendor/nordic/nrf54l_05_10_15.dtsi:754 */
			reg = < 0x5004b000 0x1000 >;           /* in zephyr/dts/vendor/nordic/nrf54l_05_10_15.dtsi:755 */
			#address-cells = < 0x1 >;              /* in zephyr/dts/vendor/nordic/nrf54l_05_10_15.dtsi:756 */
			#size-cells = < 0x1 >;                 /* in zephyr/dts/vendor/nordic/nrf54l_05_10_15.dtsi:757 */
			interrupts = < 0x4b 0x1 >;             /* in zephyr/dts/vendor/nordic/nrf54l_05_10_15.dtsi:758 */

			/* node '/soc/rram-controller@5004b000/rram@0' defined in zephyr/dts/vendor/nordic/nrf54l_05_10_15.dtsi:760 */
			cpuapp_rram: rram@0 {
				compatible = "soc-nv-flash";   /* in zephyr/dts/vendor/nordic/nrf54l_05_10_15.dtsi:761 */
				erase-block-size = < 0x1000 >; /* in zephyr/dts/vendor/nordic/nrf54l_05_10_15.dtsi:762 */
				write-block-size = < 0x10 >;   /* in zephyr/dts/vendor/nordic/nrf54l_05_10_15.dtsi:763 */
				reg = < 0x0 0x165000 >;        /* in zephyr/dts/vendor/nordic/nrf54l15.dtsi:28 */

				/* node '/soc/rram-controller@5004b000/rram@0/partitions' defined in zephyr/dts/vendor/nordic/nrf54l15_cpuapp_partition.dtsi:8 */
				partitions {
					compatible = "fixed-partitions"; /* in zephyr/dts/vendor/nordic/nrf54l15_cpuapp_partition.dtsi:9 */
					#address-cells = < 0x1 >;        /* in zephyr/dts/vendor/nordic/nrf54l15_cpuapp_partition.dtsi:10 */
					#size-cells = < 0x1 >;           /* in zephyr/dts/vendor/nordic/nrf54l15_cpuapp_partition.dtsi:11 */

					/* node '/soc/rram-controller@5004b000/rram@0/partitions/partition@0' defined in zephyr/dts/vendor/nordic/nrf54l15_cpuapp_partition.dtsi:13 */
					boot_partition: partition@0 {
						label = "mcuboot";     /* in zephyr/dts/vendor/nordic/nrf54l15_cpuapp_partition.dtsi:14 */
						reg = < 0x0 0x10000 >; /* in zephyr/dts/vendor/nordic/nrf54l15_cpuapp_partition.dtsi:15 */
					};

					/* node '/soc/rram-controller@5004b000/rram@0/partitions/partition@10000' defined in zephyr/dts/vendor/nordic/nrf54l15_cpuapp_partition.dtsi:18 */
					slot0_partition: partition@10000 {
						label = "image-0";         /* in zephyr/dts/vendor/nordic/nrf54l15_cpuapp_partition.dtsi:19 */
						reg = < 0x10000 0xa6000 >; /* in zephyr/dts/vendor/nordic/nrf54l15_cpuapp_partition.dtsi:20 */
					};

					/* node '/soc/rram-controller@5004b000/rram@0/partitions/partition@b6000' defined in zephyr/dts/vendor/nordic/nrf54l15_cpuapp_partition.dtsi:23 */
					slot1_partition: partition@b6000 {
						label = "image-1";         /* in zephyr/dts/vendor/nordic/nrf54l15_cpuapp_partition.dtsi:24 */
						reg = < 0xb6000 0xa6000 >; /* in zephyr/dts/vendor/nordic/nrf54l15_cpuapp_partition.dtsi:25 */
					};

					/* node '/soc/rram-controller@5004b000/rram@0/partitions/partition@15c000' defined in zephyr/dts/vendor/nordic/nrf54l15_cpuapp_partition.dtsi:28 */
					storage_partition: partition@15c000 {
						label = "storage";         /* in zephyr/dts/vendor/nordic/nrf54l15_cpuapp_partition.dtsi:29 */
						reg = < 0x15c000 0x9000 >; /* in zephyr/dts/vendor/nordic/nrf54l15_cpuapp_partition.dtsi:30 */
					};
				};
			};
		};

		/* node '/soc/memory@50041000' defined in zephyr/dts/vendor/nordic/nrf54l_05_10_15.dtsi:767 */
		nrf_mpc: memory@50041000 {
			compatible = "nordic,nrf-mpc";     /* in zephyr/dts/vendor/nordic/nrf54l_05_10_15.dtsi:768 */
			reg = < 0x50041000 0x1000 >;       /* in zephyr/dts/vendor/nordic/nrf54l_05_10_15.dtsi:769 */
			#address-cells = < 0x1 >;          /* in zephyr/dts/vendor/nordic/nrf54l_05_10_15.dtsi:770 */
			#size-cells = < 0x1 >;             /* in zephyr/dts/vendor/nordic/nrf54l_05_10_15.dtsi:771 */
			override-num = < 0x5 >;            /* in zephyr/dts/vendor/nordic/nrf54l_05_10_15.dtsi:772 */
			override-granularity = < 0x1000 >; /* in zephyr/dts/vendor/nordic/nrf54l_05_10_15.dtsi:773 */
		};

		/* node '/soc/cpuapp-ppb-bus' defined in zephyr/dts/vendor/nordic/nrf54l_05_10_15.dtsi:776 */
		cpuapp_ppb: cpuapp-ppb-bus {
			#address-cells = < 0x1 >;  /* in zephyr/dts/vendor/nordic/nrf54l_05_10_15.dtsi:777 */
			#size-cells = < 0x1 >;     /* in zephyr/dts/vendor/nordic/nrf54l_05_10_15.dtsi:778 */
			compatible = "simple-bus"; /* in zephyr/dts/arm/nordic/nrf54l_05_10_15_cpuapp.dtsi:70 */
			ranges;                    /* in zephyr/dts/arm/nordic/nrf54l_05_10_15_cpuapp.dtsi:71 */

			/* node '/soc/cpuapp-ppb-bus/interrupt-controller@e000e100' defined in zephyr/dts/vendor/nordic/nrf54l_05_10_15.dtsi:780 */
			cpuapp_nvic: nvic: interrupt-controller@e000e100 {
				#address-cells = < 0x1 >;            /* in zephyr/dts/vendor/nordic/nrf54l_05_10_15.dtsi:781 */
				compatible = "arm,v8m-nvic";         /* in zephyr/dts/vendor/nordic/nrf54l_05_10_15.dtsi:782 */
				reg = < 0xe000e100 0xc00 >;          /* in zephyr/dts/vendor/nordic/nrf54l_05_10_15.dtsi:783 */
				arm,num-irq-priority-bits = < 0x3 >; /* in zephyr/dts/vendor/nordic/nrf54l_05_10_15.dtsi:784 */
				interrupt-controller;                /* in zephyr/dts/vendor/nordic/nrf54l_05_10_15.dtsi:785 */
				#interrupt-cells = < 0x2 >;          /* in zephyr/dts/vendor/nordic/nrf54l_05_10_15.dtsi:786 */
				phandle = < 0x2 >;                   /* in zephyr/dts/arm/nordic/nrf54l_05_10_15_cpuapp.dtsi:29 */
			};

			/* node '/soc/cpuapp-ppb-bus/timer@e000e010' defined in zephyr/dts/vendor/nordic/nrf54l_05_10_15.dtsi:789 */
			cpuapp_systick: systick: timer@e000e010 {
				compatible = "arm,armv8m-systick"; /* in zephyr/dts/vendor/nordic/nrf54l_05_10_15.dtsi:790 */
				reg = < 0xe000e010 0x10 >;         /* in zephyr/dts/vendor/nordic/nrf54l_05_10_15.dtsi:791 */
				status = "disabled";               /* in zephyr/dts/vendor/nordic/nrf54l_05_10_15.dtsi:792 */
			};
		};
	};

	/* node '/chosen' defined in zephyr/dts/arm/nordic/nrf54l_05_10_15_cpuapp.dtsi:22 */
	chosen {
		zephyr,bt-hci = &bt_hci_sdc;                /* in zephyr/dts/arm/nordic/nrf54l_05_10_15_cpuapp.dtsi:23 */
		zephyr,entropy = &psa_rng;                  /* in zephyr/dts/arm/nordic/nrf54l_05_10_15_cpuapp.dtsi:24 */
		zephyr,console = &uart20;                   /* in zephyr/boards/nordic/nrf54l15dk/nrf54l_05_10_15_cpuapp_common.dtsi:13 */
		zephyr,shell-uart = &uart20;                /* in zephyr/boards/nordic/nrf54l15dk/nrf54l_05_10_15_cpuapp_common.dtsi:14 */
		zephyr,uart-mcumgr = &uart20;               /* in zephyr/boards/nordic/nrf54l15dk/nrf54l_05_10_15_cpuapp_common.dtsi:15 */
		zephyr,bt-mon-uart = &uart20;               /* in zephyr/boards/nordic/nrf54l15dk/nrf54l_05_10_15_cpuapp_common.dtsi:16 */
		zephyr,bt-c2h-uart = &uart20;               /* in zephyr/boards/nordic/nrf54l15dk/nrf54l_05_10_15_cpuapp_common.dtsi:17 */
		zephyr,flash-controller = &rram_controller; /* in zephyr/boards/nordic/nrf54l15dk/nrf54l_05_10_15_cpuapp_common.dtsi:18 */
		zephyr,flash = &cpuapp_rram;                /* in zephyr/boards/nordic/nrf54l15dk/nrf54l_05_10_15_cpuapp_common.dtsi:19 */
		zephyr,ieee802154 = &ieee802154;            /* in zephyr/boards/nordic/nrf54l15dk/nrf54l_05_10_15_cpuapp_common.dtsi:20 */
		zephyr,boot-mode = &boot_mode0;             /* in zephyr/boards/nordic/nrf54l15dk/nrf54l_05_10_15_cpuapp_common.dtsi:21 */
		zephyr,code-partition = &slot0_partition;   /* in zephyr/boards/nordic/nrf54l15dk/nrf54l15dk_nrf54l15_cpuapp.dts:17 */
		zephyr,sram = &cpuapp_sram;                 /* in zephyr/boards/nordic/nrf54l15dk/nrf54l15dk_nrf54l15_cpuapp.dts:18 */
	};

	/* node '/rng' defined in zephyr/dts/arm/nordic/nrf54l_05_10_15_cpuapp.dtsi:33 */
	rng: rng {
		status = "disabled";                      /* in zephyr/dts/arm/nordic/nrf54l_05_10_15_cpuapp.dtsi:34 */
		compatible = "nordic,nrf-cracen-ctrdrbg"; /* in zephyr/dts/arm/nordic/nrf54l_05_10_15_cpuapp.dtsi:35 */
	};

	/* node '/psa-rng' defined in zephyr/dts/arm/nordic/nrf54l_05_10_15_cpuapp.dtsi:38 */
	psa_rng: psa-rng {
		compatible = "zephyr,psa-crypto-rng"; /* in zephyr/dts/arm/nordic/nrf54l_05_10_15_cpuapp.dtsi:39 */
		status = "okay";                      /* in zephyr/dts/arm/nordic/nrf54l_05_10_15_cpuapp.dtsi:40 */
	};

	/* node '/leds' defined in zephyr/boards/nordic/nrf54l15dk/nrf54l15dk_common.dtsi:10 */
	leds {
		compatible = "gpio-leds"; /* in zephyr/boards/nordic/nrf54l15dk/nrf54l15dk_common.dtsi:11 */

		/* node '/leds/led_0' defined in zephyr/boards/nordic/nrf54l15dk/nrf54l15dk_common.dtsi:13 */
		led0: led_0 {
			gpios = < &gpio2 0x9 0x0 >; /* in zephyr/boards/nordic/nrf54l15dk/nrf54l15dk_common.dtsi:14 */
			label = "Green LED 0";      /* in zephyr/boards/nordic/nrf54l15dk/nrf54l15dk_common.dtsi:15 */
		};

		/* node '/leds/led_1' defined in zephyr/boards/nordic/nrf54l15dk/nrf54l15dk_common.dtsi:18 */
		led1: led_1 {
			gpios = < &gpio1 0xa 0x0 >; /* in zephyr/boards/nordic/nrf54l15dk/nrf54l15dk_common.dtsi:19 */
			label = "Green LED 1";      /* in zephyr/boards/nordic/nrf54l15dk/nrf54l15dk_common.dtsi:20 */
		};

		/* node '/leds/led_2' defined in zephyr/boards/nordic/nrf54l15dk/nrf54l15dk_common.dtsi:23 */
		led2: led_2 {
			gpios = < &gpio2 0x7 0x0 >; /* in zephyr/boards/nordic/nrf54l15dk/nrf54l15dk_common.dtsi:24 */
			label = "Green LED 2";      /* in zephyr/boards/nordic/nrf54l15dk/nrf54l15dk_common.dtsi:25 */
		};

		/* node '/leds/led_3' defined in zephyr/boards/nordic/nrf54l15dk/nrf54l15dk_common.dtsi:28 */
		led3: led_3 {
			gpios = < &gpio1 0xe 0x0 >; /* in zephyr/boards/nordic/nrf54l15dk/nrf54l15dk_common.dtsi:29 */
			label = "Green LED 3";      /* in zephyr/boards/nordic/nrf54l15dk/nrf54l15dk_common.dtsi:30 */
		};
	};

	/* node '/pwmleds' defined in zephyr/boards/nordic/nrf54l15dk/nrf54l15dk_common.dtsi:34 */
	pwmleds {
		compatible = "pwm-leds"; /* in zephyr/boards/nordic/nrf54l15dk/nrf54l15dk_common.dtsi:35 */

		/* node '/pwmleds/pwm_led_1' defined in zephyr/boards/nordic/nrf54l15dk/nrf54l15dk_common.dtsi:43 */
		pwm_led1: pwm_led_1 {
			pwms = < &pwm20 0x0 0x1312d00 0x0 >; /* in zephyr/boards/nordic/nrf54l15dk/nrf54l15dk_common.dtsi:44 */
		};
	};

	/* node '/buttons' defined in zephyr/boards/nordic/nrf54l15dk/nrf54l15dk_common.dtsi:48 */
	buttons {
		compatible = "gpio-keys"; /* in zephyr/boards/nordic/nrf54l15dk/nrf54l15dk_common.dtsi:49 */

		/* node '/buttons/button_0' defined in zephyr/boards/nordic/nrf54l15dk/nrf54l15dk_common.dtsi:51 */
		button0: button_0 {
			gpios = < &gpio1 0xd 0x11 >; /* in zephyr/boards/nordic/nrf54l15dk/nrf54l15dk_common.dtsi:52 */
			label = "Push button 0";     /* in zephyr/boards/nordic/nrf54l15dk/nrf54l15dk_common.dtsi:53 */
			zephyr,code = < 0xb >;       /* in zephyr/boards/nordic/nrf54l15dk/nrf54l15dk_common.dtsi:54 */
		};

		/* node '/buttons/button_1' defined in zephyr/boards/nordic/nrf54l15dk/nrf54l15dk_common.dtsi:57 */
		button1: button_1 {
			gpios = < &gpio1 0x9 0x11 >; /* in zephyr/boards/nordic/nrf54l15dk/nrf54l15dk_common.dtsi:58 */
			label = "Push button 1";     /* in zephyr/boards/nordic/nrf54l15dk/nrf54l15dk_common.dtsi:59 */
			zephyr,code = < 0x2 >;       /* in zephyr/boards/nordic/nrf54l15dk/nrf54l15dk_common.dtsi:60 */
		};

		/* node '/buttons/button_2' defined in zephyr/boards/nordic/nrf54l15dk/nrf54l15dk_common.dtsi:63 */
		button2: button_2 {
			gpios = < &gpio1 0x8 0x11 >; /* in zephyr/boards/nordic/nrf54l15dk/nrf54l15dk_common.dtsi:64 */
			label = "Push button 2";     /* in zephyr/boards/nordic/nrf54l15dk/nrf54l15dk_common.dtsi:65 */
			zephyr,code = < 0x3 >;       /* in zephyr/boards/nordic/nrf54l15dk/nrf54l15dk_common.dtsi:66 */
		};

		/* node '/buttons/button_3' defined in zephyr/boards/nordic/nrf54l15dk/nrf54l15dk_common.dtsi:69 */
		button3: button_3 {
			gpios = < &gpio0 0x4 0x11 >; /* in zephyr/boards/nordic/nrf54l15dk/nrf54l15dk_common.dtsi:70 */
			label = "Push button 3";     /* in zephyr/boards/nordic/nrf54l15dk/nrf54l15dk_common.dtsi:71 */
			zephyr,code = < 0x4 >;       /* in zephyr/boards/nordic/nrf54l15dk/nrf54l15dk_common.dtsi:72 */
		};
	};

	/* node '/aliases' defined in zephyr/boards/nordic/nrf54l15dk/nrf54l15dk_common.dtsi:76 */
	aliases {
		led0 = &led0;               /* in zephyr/boards/nordic/nrf54l15dk/nrf54l15dk_common.dtsi:77 */
		led1 = &led1;               /* in zephyr/boards/nordic/nrf54l15dk/nrf54l15dk_common.dtsi:78 */
		led2 = &led2;               /* in zephyr/boards/nordic/nrf54l15dk/nrf54l15dk_common.dtsi:79 */
		led3 = &led3;               /* in zephyr/boards/nordic/nrf54l15dk/nrf54l15dk_common.dtsi:80 */
		pwm-led0 = &pwm_led1;       /* in zephyr/boards/nordic/nrf54l15dk/nrf54l15dk_common.dtsi:81 */
		sw0 = &button0;             /* in zephyr/boards/nordic/nrf54l15dk/nrf54l15dk_common.dtsi:82 */
		sw1 = &button1;             /* in zephyr/boards/nordic/nrf54l15dk/nrf54l15dk_common.dtsi:83 */
		sw2 = &button2;             /* in zephyr/boards/nordic/nrf54l15dk/nrf54l15dk_common.dtsi:84 */
		sw3 = &button3;             /* in zephyr/boards/nordic/nrf54l15dk/nrf54l15dk_common.dtsi:85 */
		watchdog0 = &wdt31;         /* in zephyr/boards/nordic/nrf54l15dk/nrf54l15dk_common.dtsi:86 */
		mcuboot-button0 = &button0; /* in zephyr/boards/nordic/nrf54l15dk/nrf54l_05_10_15_cpuapp_common.dtsi:25 */
		mcuboot-led0 = &led0;       /* in zephyr/boards/nordic/nrf54l15dk/nrf54l_05_10_15_cpuapp_common.dtsi:26 */
	};

	/* node '/nordic_expansion_header' defined in zephyr/boards/nordic/nrf54l15dk/nrf54l15dk_common.dtsi:93 */
	nordic_expansion_header: nordic_expansion_header {
		compatible = "nordic,expansion-board-header"; /* in zephyr/boards/nordic/nrf54l15dk/nrf54l15dk_common.dtsi:94 */
		#gpio-cells = < 0x2 >;                        /* in zephyr/boards/nordic/nrf54l15dk/nrf54l15dk_common.dtsi:95 */
		gpio-map-mask = < 0xffffffff 0xffffffc0 >;    /* in zephyr/boards/nordic/nrf54l15dk/nrf54l15dk_common.dtsi:96 */
		gpio-map-pass-thru = < 0x0 0x3f >;            /* in zephyr/boards/nordic/nrf54l15dk/nrf54l15dk_common.dtsi:97 */
		gpio-map = < 0x4 0x0 &gpio1 0x4 0x0 >,
		           < 0x5 0x0 &gpio1 0x5 0x0 >,
		           < 0x6 0x0 &gpio1 0x6 0x0 >,
		           < 0x7 0x0 &gpio1 0x7 0x0 >,
		           < 0x8 0x0 &gpio1 0x8 0x0 >,
		           < 0x9 0x0 &gpio1 0x9 0x0 >,
		           < 0xa 0x0 &gpio1 0xa 0x0 >,
		           < 0xb 0x0 &gpio1 0xb 0x0 >,
		           < 0xc 0x0 &gpio1 0xc 0x0 >,
		           < 0xd 0x0 &gpio1 0xd 0x0 >,
		           < 0xe 0x0 &gpio1 0xe 0x0 >;        /* in zephyr/boards/nordic/nrf54l15dk/nrf54l15dk_common.dtsi:98 */
	};
};
